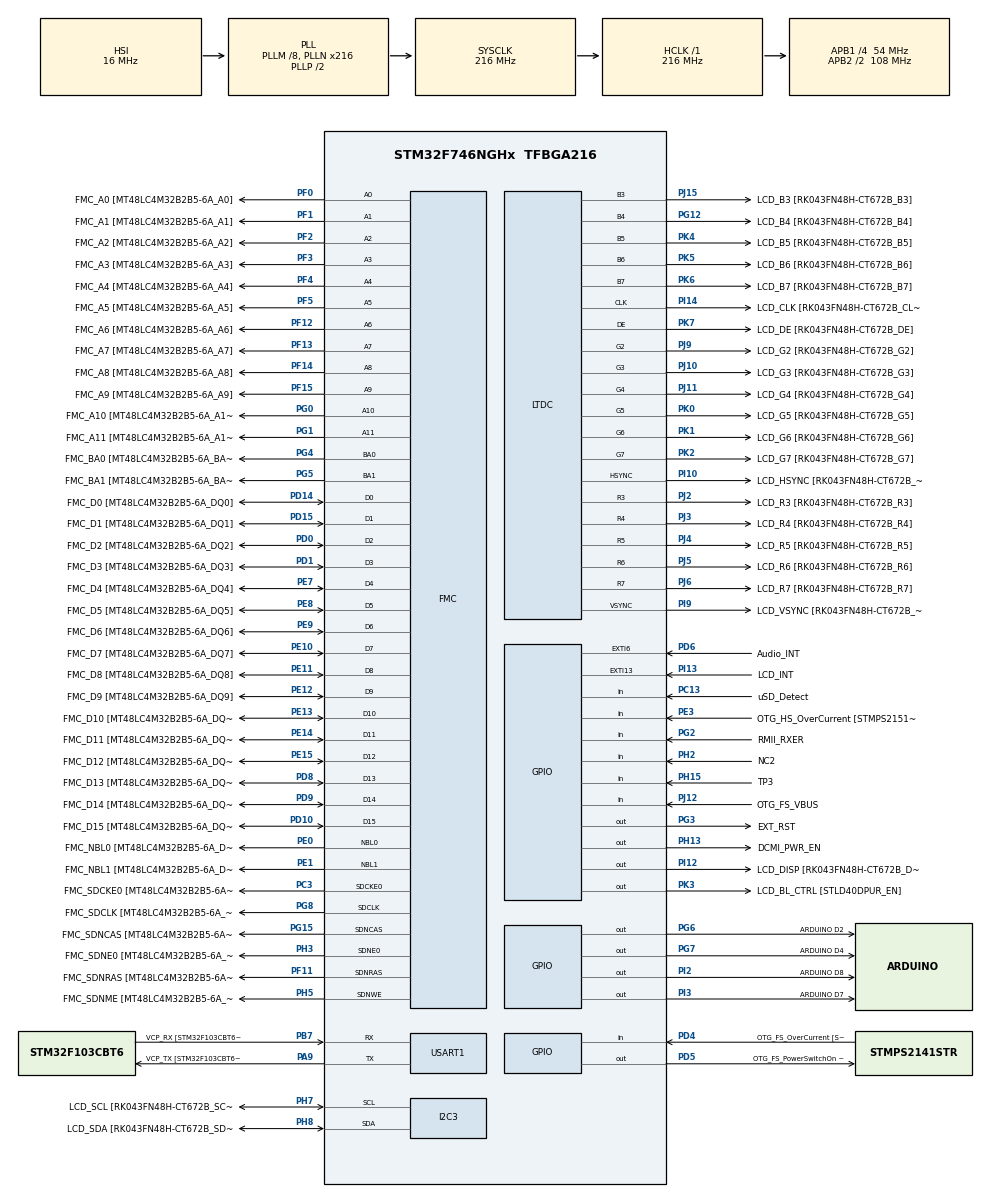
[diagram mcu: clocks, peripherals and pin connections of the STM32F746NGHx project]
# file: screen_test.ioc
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CORTEX_M7.CPU_DCache=Disabled
CORTEX_M7.CPU_ICache=Disabled
CORTEX_M7.PREFETCH_ENABLE=0
FMC.CASLatency1=FMC_SDRAM_CAS_LATENCY_3
FMC.ExitSelfRefreshDelay1=7
FMC.LoadToActiveDelay1=2
FMC.RCDDelay1=2
FMC.RPDelay1=2
FMC.RPDelay2=2
FMC.ReadBurst1=FMC_SDRAM_RBURST_ENABLE
FMC.ReadBurst2=FMC_SDRAM_RBURST_ENABLE
FMC.RowCycleDelay1=7
FMC.RowCycleDelay2=7
FMC.SDClockPeriod1=FMC_SDRAM_CLOCK_PERIOD_2
FMC.SDClockPeriod2=FMC_SDRAM_CLOCK_PERIOD_2
FMC.SelfRefreshTime1=4
FMC.WriteRecoveryTime1=3
FREERTOS.Tasks01=defaultTask,24,128,StartDefaultTask,Default,NULL,Dynamic,NULL,NULL;TSResponse,40,128,StartTSResponse,Default,NULL,Dynamic,NULL,NULL;OscDrawing,40,128,StartOscDrawing,Default,NULL,Dynamic,NULL,NULL
I2C3.Timing=0x20404768
LTDC.ActiveH=SCREEN_HEIGHT
LTDC.ActiveW=SCREEN_WIDTH
LTDC.HBP=13
LTDC.HFP=32
LTDC.HSync=41
LTDC.VSync=10
Mcu.Family=STM32F7
Mcu.Name=STM32F746NGHx
Mcu.Package=TFBGA216
Mcu.UserConstants=SCREEN_WIDTH,480;SCREEN_HEIGHT,272
NVIC.DMA2D_IRQn=true\:5\:0\:false\:false\:true\:true\:true\:true\:true
NVIC.EXTI15_10_IRQn=true\:5\:0\:false\:false\:true\:true\:true\:true\:true
NVIC.PriorityGroup=NVIC_PRIORITYGROUP_4
PA0/WKUP.GPIO_Label=ARDUINO A0
PA0/WKUP.GPIO_Mode=GPIO_MODE_ANALOG
PA0/WKUP.GPIO_PuPd=GPIO_NOPULL
PA0/WKUP.Signal=ADCx_IN0
PA1.GPIO_Label=RMII_REF_CLK [LAN8742A-CZ-TR_REFCLK0]
PA1.Signal=ETH_REF_CLK
PA10.GPIO_Label=OTG_FS_ID
PA10.Signal=USB_OTG_FS_ID
PA11.GPIO_Label=OTG_FS_N
PA11.Signal=USB_OTG_FS_DM
PA12.GPIO_Label=OTG_FS_P
PA12.Signal=USB_OTG_FS_DP
PA13.GPIO_Label=SWDIO
PA13.Signal=SYS_JTMS-SWDIO
PA14.GPIO_Label=SWCLK
PA14.Signal=SYS_JTCK-SWCLK
PA15.GPIO_Label=ARDUINO PWM/D9
PA15.GPIO_ModeDefaultPP=GPIO_MODE_AF_PP
PA15.GPIO_PuPd=GPIO_NOPULL
PA15.GPIO_Speed=GPIO_SPEED_FREQ_LOW
PA15.Signal=S_TIM2_CH1_ETR
PA2.GPIO_Label=RMII_MDIO [LAN8742A-CZ-TR_MDIO]
PA2.Signal=ETH_MDIO
PA3.GPIO_Label=ULPI_D0 [USB3320C-EZK_D0]
PA3.Signal=USB_OTG_HS_ULPI_D0
PA4.GPIO_Label=DCMI_HSYNC
PA4.Signal=DCMI_HSYNC
PA5.GPIO_Label=ULPI_CLK [USB3320C-EZK_CLKOUT]
PA5.Signal=USB_OTG_HS_ULPI_CK
PA6.Signal=DCMI_PIXCLK
PA7.GPIO_Label=RMII_CRS_DV [LAN8742A-CZ-TR_CRS_DV]
PA7.Signal=ETH_CRS_DV
PA8.GPIO_Label=ARDUINO PWM/D10
PA8.GPIO_ModeDefaultPP=GPIO_MODE_AF_PP
PA8.GPIO_PuPd=GPIO_NOPULL
PA8.GPIO_Speed=GPIO_SPEED_FREQ_LOW
PA8.Signal=S_TIM1_CH1
PA9.GPIO_Label=VCP_TX [STM32F103CBT6_PA3]
PA9.GPIO_Mode=GPIO_MODE_AF_PP
PA9.GPIO_PuPd=GPIO_NOPULL
PA9.GPIO_Speed=GPIO_SPEED_FREQ_LOW
PA9.Mode=Asynchronous
PA9.Signal=USART1_TX
PB0.GPIO_Label=ULPI_D1 [USB3320C-EZK_D1]
PB0.Signal=USB_OTG_HS_ULPI_D1
PB1.GPIO_Label=ULPI_D2 [USB3320C-EZK_D2]
PB1.Signal=USB_OTG_HS_ULPI_D2
PB10.GPIO_Label=ULPI_D3 [USB3320C-EZK_D3]
PB10.Signal=USB_OTG_HS_ULPI_D3
PB11.GPIO_Label=ULPI_D4 [USB3320C-EZK_D4]
PB11.Signal=USB_OTG_HS_ULPI_D4
PB12.GPIO_Label=ULPI_D5 [USB3320C-EZK_D5]
PB12.Signal=USB_OTG_HS_ULPI_D5
PB13.GPIO_Label=ULPI_D6 [USB3320C-EZK_D6]
PB13.Signal=USB_OTG_HS_ULPI_D6
PB14.GPIO_Label=ARDUINO MISO/D12
PB14.GPIO_Mode=GPIO_MODE_AF_PP
PB14.GPIO_PuPd=GPIO_NOPULL
PB14.GPIO_Speed=GPIO_SPEED_FREQ_LOW
PB14.Signal=SPI2_MISO
PB15.GPIO_Label=ARDUINO MOSI/PWM/D11
PB15.GPIO_Mode=GPIO_MODE_AF_PP
PB15.GPIO_PuPd=GPIO_NOPULL
PB15.GPIO_Speed=GPIO_SPEED_FREQ_LOW
PB15.Signal=SPI2_MOSI
PB2.Signal=QUADSPI_CLK
PB3.GPIO_Label=SWO
PB3.Signal=SYS_JTDO-SWO
PB4.GPIO_Label=ARDUINO PWM/D3
PB4.GPIO_ModeDefaultPP=GPIO_MODE_AF_PP
PB4.GPIO_PuPd=GPIO_NOPULL
PB4.GPIO_Speed=GPIO_SPEED_FREQ_LOW
PB4.Signal=S_TIM3_CH1
PB5.GPIO_Label=ULPI_D7 [USB3320C-EZK_D7]
PB5.Signal=USB_OTG_HS_ULPI_D7
PB6.GPIO_Label=QSPI_NCS [N25Q128A13EF840E_S]
PB6.Signal=QUADSPI_BK1_NCS
PB7.GPIO_Label=VCP_RX [STM32F103CBT6_PA2]
PB7.GPIO_Mode=GPIO_MODE_AF_PP
PB7.GPIO_PuPd=GPIO_NOPULL
PB7.GPIO_Speed=GPIO_SPEED_FREQ_LOW
PB7.Mode=Asynchronous
PB7.Signal=USART1_RX
PB8.GPIO_Label=ARDUINO SCL/D15
PB8.GPIO_Mode=GPIO_MODE_AF_OD
PB8.GPIO_PuPd=GPIO_NOPULL
PB8.GPIO_Speed=GPIO_SPEED_FREQ_LOW
PB8.Signal=I2C1_SCL
PB9.GPIO_Label=ARDUINO SDA/D14
PB9.GPIO_Mode=GPIO_MODE_AF_OD
PB9.GPIO_PuPd=GPIO_NOPULL
PB9.GPIO_Speed=GPIO_SPEED_FREQ_LOW
PB9.Signal=I2C1_SDA
PC0.GPIO_Label=ULPI_STP [USB3320C-EZK_STP]
PC0.Signal=USB_OTG_HS_ULPI_STP
PC1.GPIO_Label=RMII_MDC [LAN8742A-CZ-TR_MDC]
PC1.Signal=ETH_MDC
PC10.GPIO_Label=SDMMC_D2
PC10.Signal=SDMMC1_D2
PC11.GPIO_Label=SDMMC_D3
PC11.Signal=SDMMC1_D3
PC12.GPIO_Label=SDMMC_CK
PC12.Signal=SDMMC1_CK
PC13.GPIO_Label=uSD_Detect
PC13.Signal=GPIO_Input
PC14/OSC32_IN.GPIO_Label=RCC_OSC32_IN
PC14/OSC32_IN.Signal=RCC_OSC32_IN
PC15/OSC32_OUT.GPIO_Label=RCC_OSC32_OUT
PC15/OSC32_OUT.Signal=RCC_OSC32_OUT
PC2.GPIO_Label=ULPI_DIR [USB3320C-EZK_DIR]
PC2.Signal=USB_OTG_HS_ULPI_DIR
PC3.GPIO_Label=FMC_SDCKE0 [MT48LC4M32B2B5-6A_CKE]
PC3.Mode=SdramChipSelect1_1
PC3.Signal=FMC_SDCKE0
PC4.GPIO_Label=RMII_RXD0 [LAN8742A-CZ-TR_RXD0]
PC4.Signal=ETH_RXD0
PC5.GPIO_Label=RMII_RXD1 [LAN8742A-CZ-TR_RXD1]
PC5.Signal=ETH_RXD1
PC6.GPIO_Label=ARDUINO TX/D1
PC6.Signal=USART6_TX
PC7.GPIO_Label=ARDUINO RX/D0
PC7.Signal=USART6_RX
PC8.Signal=SDMMC1_D0
PC9.Signal=SDMMC1_D1
PD0.GPIO_Label=FMC_D2 [MT48LC4M32B2B5-6A_DQ2]
PD0.Signal=FMC_D2_DA2
PD1.GPIO_Label=FMC_D3 [MT48LC4M32B2B5-6A_DQ3]
PD1.Signal=FMC_D3_DA3
PD10.GPIO_Label=FMC_D15 [MT48LC4M32B2B5-6A_DQ15]
PD10.Signal=FMC_D15_DA15
PD11.GPIO_Label=QSPI_D0 [N25Q128A13EF840E_DQ0]
PD11.Signal=QUADSPI_BK1_IO0
PD12.GPIO_Label=QSPI_D1 [N25Q128A13EF840E_DQ1]
PD12.Signal=QUADSPI_BK1_IO1
PD13.GPIO_Label=QSPI_D3 [N25Q128A13EF840E_DQ3]
PD13.Signal=QUADSPI_BK1_IO3
PD14.GPIO_Label=FMC_D0 [MT48LC4M32B2B5-6A_DQ0]
PD14.Signal=FMC_D0_DA0
PD15.GPIO_Label=FMC_D1 [MT48LC4M32B2B5-6A_DQ1]
PD15.Signal=FMC_D1_DA1
PD2.GPIO_Label=SDMMC_D0
PD2.Signal=SDMMC1_CMD
PD3.GPIO_Label=DCMI_D5
PD3.Signal=DCMI_D5
PD4.GPIO_Label=OTG_FS_OverCurrent [STMPS2141STR_Fault]
PD4.Signal=GPIO_Input
PD5.GPIO_Label=OTG_FS_PowerSwitchOn [STMPS2141STR_EN]
PD5.PinState=GPIO_PIN_SET
PD5.Signal=GPIO_Output
PD6.GPIO_Label=Audio_INT
PD6.GPIO_ModeDefaultEXTI=GPIO_MODE_EVT_RISING
PD6.Signal=GPXTI6
PD7.GPIO_Label=SPDIF_RX0 [74LVC1G04SE_4]
PD7.Signal=SPDIFRX_IN0
PD8.GPIO_Label=FMC_D13 [MT48LC4M32B2B5-6A_DQ13]
PD8.Signal=FMC_D13_DA13
PD9.GPIO_Label=FMC_D14 [MT48LC4M32B2B5-6A_DQ14]
PD9.Signal=FMC_D14_DA14
PE0.GPIO_Label=FMC_NBL0 [MT48LC4M32B2B5-6A_DQM0]
PE0.Signal=FMC_NBL0
PE1.GPIO_Label=FMC_NBL1 [MT48LC4M32B2B5-6A_DQM1]
PE1.Signal=FMC_NBL1
PE10.GPIO_Label=FMC_D7 [MT48LC4M32B2B5-6A_DQ7]
PE10.Signal=FMC_D7_DA7
PE11.GPIO_Label=FMC_D8 [MT48LC4M32B2B5-6A_DQ8]
PE11.Signal=FMC_D8_DA8
PE12.GPIO_Label=FMC_D9 [MT48LC4M32B2B5-6A_DQ9]
PE12.Signal=FMC_D9_DA9
PE13.GPIO_Label=FMC_D10 [MT48LC4M32B2B5-6A_DQ10]
PE13.Signal=FMC_D10_DA10
PE14.GPIO_Label=FMC_D11 [MT48LC4M32B2B5-6A_DQ11]
PE14.Signal=FMC_D11_DA11
PE15.GPIO_Label=FMC_D12 [MT48LC4M32B2B5-6A_DQ12]
PE15.Signal=FMC_D12_DA12
PE2.GPIO_Label=QSPI_D2 [N25Q128A13EF840E_DQ2]
PE2.Signal=QUADSPI_BK1_IO2
PE3.GPIO_Label=OTG_HS_OverCurrent [STMPS2151STR_FAULT]
PE3.Signal=GPIO_Input
PE4.GPIO_Label=LCD_B0 [RK043FN48H-CT672B_B0]
PE4.Signal=LTDC_B0
PE5.GPIO_Label=DCMI_D6
PE5.Signal=DCMI_D6
PE6.GPIO_Label=DCMI_D7
PE6.Signal=DCMI_D7
PE7.GPIO_Label=FMC_D4 [MT48LC4M32B2B5-6A_DQ4]
PE7.Signal=FMC_D4_DA4
PE8.GPIO_Label=FMC_D5 [MT48LC4M32B2B5-6A_DQ5]
PE8.Signal=FMC_D5_DA5
PE9.GPIO_Label=FMC_D6 [MT48LC4M32B2B5-6A_DQ6]
PE9.Signal=FMC_D6_DA6
PF0.GPIO_Label=FMC_A0 [MT48LC4M32B2B5-6A_A0]
PF0.Signal=FMC_A0
PF1.GPIO_Label=FMC_A1 [MT48LC4M32B2B5-6A_A1]
PF1.Signal=FMC_A1
PF10.GPIO_Label=ARDUINO A1
PF10.GPIO_Mode=GPIO_MODE_ANALOG
PF10.GPIO_PuPd=GPIO_NOPULL
PF10.Signal=ADC3_IN8
PF11.GPIO_Label=FMC_SDNRAS [MT48LC4M32B2B5-6A_RAS]
PF11.Signal=FMC_SDNRAS
PF12.GPIO_Label=FMC_A6 [MT48LC4M32B2B5-6A_A6]
PF12.Signal=FMC_A6
PF13.GPIO_Label=FMC_A7 [MT48LC4M32B2B5-6A_A7]
PF13.Signal=FMC_A7
PF14.GPIO_Label=FMC_A8 [MT48LC4M32B2B5-6A_A8]
PF14.Signal=FMC_A8
PF15.GPIO_Label=FMC_A9 [MT48LC4M32B2B5-6A_A9]
PF15.Signal=FMC_A9
PF2.GPIO_Label=FMC_A2 [MT48LC4M32B2B5-6A_A2]
PF2.Signal=FMC_A2
PF3.GPIO_Label=FMC_A3 [MT48LC4M32B2B5-6A_A3]
PF3.Signal=FMC_A3
PF4.GPIO_Label=FMC_A4 [MT48LC4M32B2B5-6A_A4]
PF4.Signal=FMC_A4
PF5.GPIO_Label=FMC_A5 [MT48LC4M32B2B5-6A_A5]
PF5.Signal=FMC_A5
PF6.GPIO_Label=ARDUINO A5
PF6.GPIO_Mode=GPIO_MODE_ANALOG
PF6.GPIO_PuPd=GPIO_NOPULL
PF6.Signal=ADC3_IN4
PF7.GPIO_Label=ARDUINO A4
PF7.GPIO_Mode=GPIO_MODE_ANALOG
PF7.GPIO_PuPd=GPIO_NOPULL
PF7.Signal=ADC3_IN5
PF8.GPIO_Label=ARDUINO A3
PF8.GPIO_Mode=GPIO_MODE_ANALOG
PF8.GPIO_PuPd=GPIO_NOPULL
PF8.Signal=ADC3_IN6
PF9.GPIO_Label=ARDUINO A2
PF9.GPIO_Mode=GPIO_MODE_ANALOG
PF9.GPIO_PuPd=GPIO_NOPULL
PF9.Signal=ADC3_IN7
PG0.GPIO_Label=FMC_A10 [MT48LC4M32B2B5-6A_A10]
PG0.Signal=FMC_A10
PG1.GPIO_Label=FMC_A11 [MT48LC4M32B2B5-6A_A11]
PG1.Signal=FMC_A11
PG10.GPIO_Label=SAI2_SDB [WM8994ECS/R_ADCDAT1]
PG10.Signal=SAI2_SD_B
PG11.GPIO_Label=RMII_TX_EN [LAN8742A-CZ-TR_TXEN]
PG11.Signal=ETH_TX_EN
PG12.GPIO_Label=LCD_B4 [RK043FN48H-CT672B_B4]
PG12.Mode=RGB565
PG12.Signal=LTDC_B4
PG13.GPIO_Label=RMII_TXD0 [LAN8742A-CZ-TR_TXD0]
PG13.Signal=ETH_TXD0
PG14.GPIO_Label=RMII_TXD1 [LAN8742A-CZ-TR_TXD1]
PG14.Signal=ETH_TXD1
PG15.GPIO_Label=FMC_SDNCAS [MT48LC4M32B2B5-6A_CAS]
PG15.Signal=FMC_SDNCAS
PG2.GPIO_Label=RMII_RXER
PG2.Signal=GPIO_Input
PG3.GPIO_Label=EXT_RST
PG3.Signal=GPIO_Output
PG4.GPIO_Label=FMC_BA0 [MT48LC4M32B2B5-6A_BA0]
PG4.Signal=FMC_A14_BA0
PG5.GPIO_Label=FMC_BA1 [MT48LC4M32B2B5-6A_BA1]
PG5.Signal=FMC_A15_BA1
PG6.GPIO_Label=ARDUINO D2
PG6.Signal=GPIO_Output
PG7.GPIO_Label=ARDUINO D4
PG7.Signal=GPIO_Output
PG8.GPIO_Label=FMC_SDCLK [MT48LC4M32B2B5-6A_CLK]
PG8.Signal=FMC_SDCLK
PG9.GPIO_Label=DCMI_VSYNC
PG9.Signal=DCMI_VSYNC
PH0/OSC_IN.GPIO_Label=OSC_25M [NZ2520SB-25.00M_OUT]
PH0/OSC_IN.Mode=HSE-External-Oscillator
PH0/OSC_IN.Signal=RCC_OSC_IN
PH1/OSC_OUT.Mode=HSE-External-Oscillator
PH1/OSC_OUT.Signal=RCC_OSC_OUT
PH10.GPIO_Label=DCMI_D1
PH10.Signal=DCMI_D1
PH11.GPIO_Label=DCMI_D2
PH11.Signal=DCMI_D2
PH12.GPIO_Label=DCMI_D3
PH12.Signal=DCMI_D3
PH13.GPIO_Label=DCMI_PWR_EN
PH13.Signal=GPIO_Output
PH14.GPIO_Label=DCMI_D4
PH14.Signal=DCMI_D4
PH15.GPIO_Label=TP3
PH15.Signal=GPIO_Input
PH2.GPIO_Label=NC2
PH2.Signal=GPIO_Input
PH3.GPIO_Label=FMC_SDNE0 [MT48LC4M32B2B5-6A_CS]
PH3.Mode=SdramChipSelect1_1
PH3.Signal=FMC_SDNE0
PH4.GPIO_Label=ULPI_NXT [USB3320C-EZK_NXT]
PH4.Signal=USB_OTG_HS_ULPI_NXT
PH5.GPIO_Label=FMC_SDNME [MT48LC4M32B2B5-6A_WE]
PH5.Signal=FMC_SDNWE
PH6.GPIO_Label=ARDUINO PWM/D6
PH6.Signal=S_TIM12_CH1
PH7.GPIO_Label=LCD_SCL [RK043FN48H-CT672B_SCL]
PH7.Mode=I2C
PH7.Signal=I2C3_SCL
PH8.GPIO_Label=LCD_SDA [RK043FN48H-CT672B_SDA]
PH8.Mode=I2C
PH8.Signal=I2C3_SDA
PH9.GPIO_Label=DCMI_D0
PH9.Signal=DCMI_D0
PI0.GPIO_Label=ARDUINO PWM/CS/D5
PI0.GPIO_ModeDefaultPP=GPIO_MODE_AF_PP
PI0.GPIO_PuPd=GPIO_NOPULL
PI0.GPIO_Speed=GPIO_SPEED_FREQ_LOW
PI0.Signal=S_TIM5_CH4
PI1.GPIO_Label=ARDUINO SCK/D13
PI1.GPIO_Mode=GPIO_MODE_AF_PP
PI1.GPIO_PuPd=GPIO_NOPULL
PI1.GPIO_Speed=GPIO_SPEED_FREQ_LOW
PI1.Signal=SPI2_SCK
PI10.GPIO_Label=LCD_HSYNC [RK043FN48H-CT672B_HSYNC]
PI10.Mode=RGB565
PI10.Signal=LTDC_HSYNC
PI12.GPIO_Label=LCD_DISP [RK043FN48H-CT672B_DISP] 
PI12.Signal=GPIO_Output
PI13.GPIO_Label=LCD_INT
PI13.GPIO_ModeDefaultEXTI=GPIO_MODE_IT_RISING
PI13.Signal=GPXTI13
PI14.GPIO_Label=LCD_CLK [RK043FN48H-CT672B_CLK]
PI14.Mode=RGB565
PI14.Signal=LTDC_CLK
PI15.GPIO_Label=LCD_R0 [RK043FN48H-CT672B_R0]
PI15.Signal=LTDC_R0
PI2.GPIO_Label=ARDUINO D8
PI2.Signal=GPIO_Output
PI3.GPIO_Label=ARDUINO D7
PI3.Signal=GPIO_Output
PI4.GPIO_Label=SAI2_MCLKA [WM8994ECS/R_MCLK1]
PI4.Signal=SAI2_MCLK_A
PI5.GPIO_Label=SAI2_SCKA [WM8994ECS/R_BCLK1]
PI5.Signal=SAI2_SCK_A
PI6.GPIO_Label=SAI2_SDA [WM8994ECS/R_DACDAT1]
PI6.Signal=SAI2_SD_A
PI7.GPIO_Label=SAI2_FSA [WM8994ECS/R_LRCLK1]
PI7.Signal=SAI2_FS_A
PI8.GPIO_Label=NC1 [TP2]
PI8.Signal=RTC_TS
PI9.GPIO_Label=LCD_VSYNC [RK043FN48H-CT672B_VSYNC]
PI9.Mode=RGB565
PI9.Signal=LTDC_VSYNC
PJ0.GPIO_Label=LCD_R1 [RK043FN48H-CT672B_R1]
PJ0.Signal=LTDC_R1
PJ1.GPIO_Label=LCD_R2 [RK043FN48H-CT672B_R2]
PJ1.Signal=LTDC_R2
PJ10.GPIO_Label=LCD_G3 [RK043FN48H-CT672B_G3]
PJ10.Mode=RGB565
PJ10.Signal=LTDC_G3
PJ11.GPIO_Label=LCD_G4 [RK043FN48H-CT672B_G4]
PJ11.Mode=RGB565
PJ11.Signal=LTDC_G4
PJ12.GPIO_Label=OTG_FS_VBUS
PJ12.Signal=GPIO_Input
PJ13.GPIO_Label=LCD_B1 [RK043FN48H-CT672B_B1]
PJ13.Signal=LTDC_B1
PJ14.GPIO_Label=LCD_B2 [RK043FN48H-CT672B_B2]
PJ14.Signal=LTDC_B2
PJ15.GPIO_Label=LCD_B3 [RK043FN48H-CT672B_B3]
PJ15.Mode=RGB565
PJ15.Signal=LTDC_B3
PJ2.GPIO_Label=LCD_R3 [RK043FN48H-CT672B_R3]
PJ2.Mode=RGB565
PJ2.Signal=LTDC_R3
PJ3.GPIO_Label=LCD_R4 [RK043FN48H-CT672B_R4]
PJ3.Mode=RGB565
PJ3.Signal=LTDC_R4
PJ4.GPIO_Label=LCD_R5 [RK043FN48H-CT672B_R5]
PJ4.Mode=RGB565
PJ4.Signal=LTDC_R5
PJ5.GPIO_Label=LCD_R6 [RK043FN48H-CT672B_R6]
PJ5.Mode=RGB565
PJ5.Signal=LTDC_R6
PJ6.GPIO_Label=LCD_R7 [RK043FN48H-CT672B_R7]
PJ6.Mode=RGB565
PJ6.Signal=LTDC_R7
PJ7.GPIO_Label=LCD_G0 [RK043FN48H-CT672B_G0]
PJ7.Signal=LTDC_G0
PJ8.GPIO_Label=LCD_G1 [RK043FN48H-CT672B_G1]
PJ8.Signal=LTDC_G1
PJ9.GPIO_Label=LCD_G2 [RK043FN48H-CT672B_G2]
PJ9.Mode=RGB565
PJ9.Signal=LTDC_G2
PK0.GPIO_Label=LCD_G5 [RK043FN48H-CT672B_G5]
PK0.Mode=RGB565
PK0.Signal=LTDC_G5
PK1.GPIO_Label=LCD_G6 [RK043FN48H-CT672B_G6]
PK1.Mode=RGB565
PK1.Signal=LTDC_G6
PK2.GPIO_Label=LCD_G7 [RK043FN48H-CT672B_G7]
PK2.Mode=RGB565
PK2.Signal=LTDC_G7
PK3.GPIO_Label=LCD_BL_CTRL [STLD40DPUR_EN]
PK3.Signal=GPIO_Output
PK4.GPIO_Label=LCD_B5 [RK043FN48H-CT672B_B5]
PK4.Mode=RGB565
PK4.Signal=LTDC_B5
PK5.GPIO_Label=LCD_B6 [RK043FN48H-CT672B_B6]
PK5.Mode=RGB565
PK5.Signal=LTDC_B6
PK6.GPIO_Label=LCD_B7 [RK043FN48H-CT672B_B7]
PK6.Mode=RGB565
PK6.Signal=LTDC_B7
PK7.GPIO_Label=LCD_DE [RK043FN48H-CT672B_DE]
PK7.Mode=RGB565
PK7.Signal=LTDC_DE
ProjectManager.HeapSize=0x200
ProjectManager.StackSize=0x400
ProjectManager.TargetToolchain=STM32CubeIDE
RCC.AHBFreq_Value=216000000
RCC.APB1CLKDivider=RCC_HCLK_DIV4
RCC.APB1Freq_Value=54000000
RCC.APB1TimFreq_Value=108000000
RCC.APB2CLKDivider=RCC_HCLK_DIV2
RCC.APB2Freq_Value=108000000
RCC.APB2TimFreq_Value=216000000
RCC.CortexFreq_Value=216000000
RCC.HCLKFreq_Value=216000000
RCC.HSE_VALUE=25000000
RCC.HSI_VALUE=16000000
RCC.LSE_VALUE=32768
RCC.PLLM=8
RCC.PLLN=216
RCC.PLLSAIN=50
RCC.PLLSourceVirtual=RCC_PLLSOURCE_HSI
RCC.SYSCLKFreq_VALUE=216000000
RCC.SYSCLKSource=RCC_SYSCLKSOURCE_PLLCLK
RCC.USBFreq_Value=216000000
RCC.VCOOutputFreq_Value=432000000
SH.ADCx_IN0.0=ADC3_IN0
SH.FMC_A0.0=FMC_A0,12b-sda1
SH.FMC_A1.0=FMC_A1,12b-sda1
SH.FMC_A10.0=FMC_A10,12b-sda1
SH.FMC_A11.0=FMC_A11,12b-sda1
SH.FMC_A14_BA0.0=FMC_BA0,FourSdramBanks1
SH.FMC_A15_BA1.0=FMC_BA1,FourSdramBanks1
SH.FMC_A2.0=FMC_A2,12b-sda1
SH.FMC_A3.0=FMC_A3,12b-sda1
SH.FMC_A4.0=FMC_A4,12b-sda1
SH.FMC_A5.0=FMC_A5,12b-sda1
SH.FMC_A6.0=FMC_A6,12b-sda1
SH.FMC_A7.0=FMC_A7,12b-sda1
SH.FMC_A8.0=FMC_A8,12b-sda1
SH.FMC_A9.0=FMC_A9,12b-sda1
SH.FMC_D0_DA0.0=FMC_D0,sd-16b-d1
SH.FMC_D10_DA10.0=FMC_D10,sd-16b-d1
SH.FMC_D11_DA11.0=FMC_D11,sd-16b-d1
SH.FMC_D12_DA12.0=FMC_D12,sd-16b-d1
SH.FMC_D13_DA13.0=FMC_D13,sd-16b-d1
SH.FMC_D14_DA14.0=FMC_D14,sd-16b-d1
SH.FMC_D15_DA15.0=FMC_D15,sd-16b-d1
SH.FMC_D1_DA1.0=FMC_D1,sd-16b-d1
SH.FMC_D2_DA2.0=FMC_D2,sd-16b-d1
SH.FMC_D3_DA3.0=FMC_D3,sd-16b-d1
SH.FMC_D4_DA4.0=FMC_D4,sd-16b-d1
SH.FMC_D5_DA5.0=FMC_D5,sd-16b-d1
SH.FMC_D6_DA6.0=FMC_D6,sd-16b-d1
SH.FMC_D7_DA7.0=FMC_D7,sd-16b-d1
SH.FMC_D8_DA8.0=FMC_D8,sd-16b-d1
SH.FMC_D9_DA9.0=FMC_D9,sd-16b-d1
SH.FMC_NBL0.0=FMC_NBL0,Sd2ByteEnable1
SH.FMC_NBL1.0=FMC_NBL1,Sd2ByteEnable1
SH.FMC_SDCLK.0=FMC_SDCLK,12b-sda1
SH.FMC_SDNCAS.0=FMC_SDNCAS,12b-sda1
SH.FMC_SDNRAS.0=FMC_SDNRAS,12b-sda1
SH.FMC_SDNWE.0=FMC_SDNWE,12b-sda1
SH.S_TIM12_CH1.0=TIM12_CH1
SH.S_TIM1_CH1.0=TIM1_CH1
SH.S_TIM2_CH1_ETR.0=TIM2_CH1
SH.S_TIM3_CH1.0=TIM3_CH1
SH.S_TIM5_CH4.0=TIM5_CH4
USART1.VirtualMode-Asynchronous=VM_ASYNC
VP_DMA2D_VS_DMA2D.Mode=DMA2D_Activate
VP_FREERTOS_VS_CMSIS_V2.Mode=CMSIS_V2
board=STM32F746G-DISCO

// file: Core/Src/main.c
/* USER CODE BEGIN Header */
/**
  ******************************************************************************
  * @file           : main.c
  * @brief          : Main program body
  ******************************************************************************
  * @attention
  *
  * Copyright (c) 2025 STMicroelectronics.
  * All rights reserved.
  *
  * This software is licensed under terms that can be found in the LICENSE file
  * in the root directory of this software component.
  * If no LICENSE file comes with this software, it is provided AS-IS.
  *
  ******************************************************************************
  */
/* USER CODE END Header */
#include "main.h"
#include "cmsis_os.h"

/* USER CODE BEGIN Includes */
#include "stlogo.h"
#include <stdio.h>
#include "fir_design.h"
#include "math.h"
#include "string.h"
#include "draw_utils.h"
/* USER CODE END Includes */

/* USER CODE BEGIN PTD */

/* in draw_utils.h
typedef enum
{
    OSC,
    SIG,
    FIL,
	PUR,
} mode_t;

typedef enum
{
	SIN,
	SQR,
	TRI,
} waveform_t;
*/

/* USER CODE END PTD */

/* USER CODE BEGIN PD */

/* in draw_utils.h
#define SCREEN_X 480
#define SCREEN_Y 272
#define FILTER_SELECT_BOX_X 95
#define FILTER_SELECT_BOX_Y 15
#define WAVEFORM_SELECT_BOX_X 160
#define WAVEFORM_SELECT_BOX_Y 50
#define FULL_SCREEN_BUT_X 160
#define FULL_SCREEN_BUT_Y 40
*/

/* USER CODE END PD */

DMA2D_HandleTypeDef hdma2d;

I2C_HandleTypeDef hi2c3;

LTDC_HandleTypeDef hltdc;

UART_HandleTypeDef huart1;

SDRAM_HandleTypeDef hsdram1;

/* Definitions for defaultTask */
osThreadId_t defaultTaskHandle;
const osThreadAttr_t defaultTask_attributes = {
  .name = "defaultTask",
  .stack_size = 128 * 4,
  .priority = (osPriority_t) osPriorityNormal,
};
/* Definitions for TSResponse */
osThreadId_t TSResponseHandle;
const osThreadAttr_t TSResponse_attributes = {
  .name = "TSResponse",
  .stack_size = 128 * 4,
  .priority = (osPriority_t) osPriorityHigh,
};
/* Definitions for OscDrawing */
osThreadId_t OscDrawingHandle;
const osThreadAttr_t OscDrawing_attributes = {
  .name = "OscDrawing",
  .stack_size = 128 * 4,
  .priority = (osPriority_t) osPriorityHigh,
};
/* USER CODE BEGIN PV */

/*in draw_utils.c
mode_t current_mode = OSC;
fir_type_t current_filter;
waveform_t current_waveform;
float waveform_mag = 1;
float waveform_freq = 10000000;
float waveform_duty = 0.3;
float osc_Vpp, osc_T, osc_V, osc_trigger, osc_freq;
int anomaly_flag = 0;
int test_flag = 0;
uint8_t databuffer[400];
uint8_t drawbuffer[400];
uint8_t prevdrawbuffer[400];
uint16_t trigger_index = 199;
uint8_t apply_filter = 0;
*/

/* USER CODE END PV */

void SystemClock_Config(void);
static void MX_GPIO_Init(void);
static void MX_USART1_UART_Init(void);
static void MX_FMC_Init(void);
static void MX_LTDC_Init(void);
static void MX_DMA2D_Init(void);
static void MX_I2C3_Init(void);
void StartDefaultTask(void *argument);
void StartTSResponse(void *argument);
void StartOscDrawing(void *argument);

/* USER CODE BEGIN PFP */

/* in draw_utils.h
void Display_DemoDescription(void);
void Display_Osc(void);
void Display_Sig_gen(void);
void Display_Filter(void);
void Display_pure(void);
void Select_Filter(uint16_t);
void Select_Waveform(uint16_t);
void touch_screen_response(void);
void draw_waveform(void);
void buffer_maker(float val, const char *prefix, char *out_buffer);
void float_to_string(float val, char *str, int decimal_places);
*/

/* USER CODE END PFP */

/* USER CODE BEGIN 0 */
/* in draw_utils.c
uint8_t status = 0, gesture = 0;
uint8_t  lcd_status = LCD_OK, touch_screen_it = 0;
TS_StateTypeDef touch_screen_state;
*/
/* USER CODE END 0 */

int main(void)
{

  /* MCU Configuration--------------------------------------------------------*/

  /* Reset of all peripherals, Initializes the Flash interface and the Systick. */
  HAL_Init();

  /* Configure the system clock */
  SystemClock_Config();

  /* Initialize all configured peripherals */
  MX_GPIO_Init();
  MX_USART1_UART_Init();
  MX_FMC_Init();
  MX_LTDC_Init();
  MX_DMA2D_Init();
  MX_I2C3_Init();
  /* USER CODE BEGIN 2 */
  BSP_LED_Init(LED1);

  /* Initialize the LCD */
  lcd_status = BSP_LCD_Init();
  if (lcd_status != LCD_OK)
  {
    Error_Handler();
  }
  BSP_LCD_LayerDefaultInit(LTDC_ACTIVE_LAYER, LCD_FRAME_BUFFER);

  /* Get the LCD X and Y sizes */
  uint32_t lcd_x_size = BSP_LCD_GetXSize();
  uint32_t lcd_y_size = BSP_LCD_GetYSize();

  Display_DemoDescription();

  /* Set the LCD background and text colors */
  BSP_LCD_DisplayOn();
  BSP_LCD_Clear(LCD_COLOR_WHITE);
  BSP_LCD_SetBackColor(LCD_COLOR_WHITE);
  BSP_LCD_SetTextColor(LCD_COLOR_BLUE);

  BSP_LCD_DrawRect(50, 50, 100, 50);

  /* Display a string at the center of the screen */
  BSP_LCD_DisplayStringAt(0, LINE(5), (uint8_t *)"LCD Test", CENTER_MODE);

  /* Draw a rectangle */
  BSP_LCD_SetTextColor(LCD_COLOR_RED);

  /* Draw a filled circle */
  BSP_LCD_SetTextColor(LCD_COLOR_GREEN);
  BSP_LCD_FillCircle(150, 150, 30);

  /* Display the sizes on the LCD */
  char size_message[50];
  snprintf(size_message, sizeof(size_message), "X: %lu, Y: %lu", lcd_x_size, lcd_y_size);
  BSP_LCD_DisplayStringAt(0, LINE(6), (uint8_t *)size_message, CENTER_MODE);

  status = BSP_TS_Init(SCREEN_WIDTH, SCREEN_HEIGHT);
  BSP_TS_ITConfig();
  status = BSP_TS_ITGetStatus();

  /* ping test start */
  BSP_LCD_Clear(LCD_COLOR_BLACK);
  BSP_LCD_SetBackColor(LCD_COLOR_BLACK);
  BSP_LCD_SetTextColor(LCD_COLOR_YELLOW);

  Display_Osc();
  for(int i = 0; i < 400; ++i){
	  databuffer[i] = i % 255;
  }

  /* USER CODE END 2 */

  /* Init scheduler */
  osKernelInitialize();

  /* Create the thread(s) */
  /* creation of defaultTask */
  defaultTaskHandle = osThreadNew(StartDefaultTask, NULL, &defaultTask_attributes);

  /* creation of TSResponse */
  TSResponseHandle = osThreadNew(StartTSResponse, NULL, &TSResponse_attributes);

  /* creation of OscDrawing */
  OscDrawingHandle = osThreadNew(StartOscDrawing, NULL, &OscDrawing_attributes);

  /* Start scheduler */
  osKernelStart();

  /* We should never get here as control is now taken by the scheduler */

  /* Infinite loop */
  /* USER CODE BEGIN WHILE */
  while (1)
  {
	  if(touch_screen_it)
	  {
//		  touch_screen_response();
//		BSP_TS_ITClear();
//		BSP_TS_GetState(&touch_screen_state);
//		BSP_TS_Get_GestureId(&touch_screen_state);
//		if(touch_screen_state.gestureId != 0)
//			gesture = touch_screen_state.gestureId;
//		touch_screen_it = 0;
//		//	BSP_LCD_DisplayStringAt(0, LINE(5), (uint8_t *)"Touched", CENTER_MODE);
//		if(current_mode == PUR){
//			if(touch_screen_state.touchY[0] < SCREEN_Y - FULL_SCREEN_BUT_Y){
//				Display_Osc();
//				current_mode = OSC;
//				continue;
//			}
//		}
//		if(touch_screen_state.touchX[0] < 320 && touch_screen_state.touchX[0] > 160 && touch_screen_state.touchY[0] < 50){
//			Display_Sig_gen();
//			current_mode = SIG;
//		}
//		if(touch_screen_state.touchX[0] < 160 && touch_screen_state.touchY[0] < 50){
//			current_mode = OSC;
//			Display_Osc();
//		}
//		if(touch_screen_state.touchX[0] > 320 && touch_screen_state.touchY[0] < 50){
//			Display_Filter();
//			current_mode = FIL;
//		}
//		switch(current_mode){
//		case OSC:
//			if(touch_screen_state.touchY[0] > SCREEN_Y - FULL_SCREEN_BUT_Y && touch_screen_state.touchX[0] > SCREEN_X - FULL_SCREEN_BUT_X){
//				current_mode = PUR;
//				Display_pure();
//			}
//			break;
//		case SIG:
//			if(touch_screen_state.touchY[0] > 100 && touch_screen_state.touchY[0] < 200){
//				for(uint16_t j = 0; j < 3; j++){
//					if((touch_screen_state.touchX[0] > (WAVEFORM_SELECT_BOX_X*j)) && (touch_screen_state.touchX[0] < WAVEFORM_SELECT_BOX_X * (1 + j))){
//						Select_Waveform(j);
//						break;
//					}
//				}
//			}
//			break;
//		case FIL:
//			if(touch_screen_state.touchY[0] > 222){
//				for(uint16_t j = 0; j < 4; ++j){
//					if((touch_screen_state.touchX[0] > FILTER_SELECT_BOX_X * (j + 1)) && (touch_screen_state.touchX[0] < FILTER_SELECT_BOX_X * (j + 2))){
//						Select_Filter(j);
//						break;
//					}
//				}
//			}
//			break;
//		default:
//			break;
//		}
	  }
    /* USER CODE END WHILE */

  }
}

void SystemClock_Config(void)
{
  RCC_OscInitTypeDef RCC_OscInitStruct = {0};
  RCC_ClkInitTypeDef RCC_ClkInitStruct = {0};

  /** Configure the main internal regulator output voltage
  */
  __HAL_RCC_PWR_CLK_ENABLE();
  __HAL_PWR_VOLTAGESCALING_CONFIG(PWR_REGULATOR_VOLTAGE_SCALE1);

  /** Initializes the RCC Oscillators according to the specified parameters
  * in the RCC_OscInitTypeDef structure.
  */
  RCC_OscInitStruct.OscillatorType = RCC_OSCILLATORTYPE_HSI;
  RCC_OscInitStruct.HSIState = RCC_HSI_ON;
  RCC_OscInitStruct.HSICalibrationValue = RCC_HSICALIBRATION_DEFAULT;
  RCC_OscInitStruct.PLL.PLLState = RCC_PLL_ON;
  RCC_OscInitStruct.PLL.PLLSource = RCC_PLLSOURCE_HSI;
  RCC_OscInitStruct.PLL.PLLM = 8;
  RCC_OscInitStruct.PLL.PLLN = 216;
  RCC_OscInitStruct.PLL.PLLP = RCC_PLLP_DIV2;
  RCC_OscInitStruct.PLL.PLLQ = 2;
  if (HAL_RCC_OscConfig(&RCC_OscInitStruct) != HAL_OK)
  {
    Error_Handler();
  }

  /** Activate the Over-Drive mode
  */
  if (HAL_PWREx_EnableOverDrive() != HAL_OK)
  {
    Error_Handler();
  }

  /** Initializes the CPU, AHB and APB buses clocks
  */
  RCC_ClkInitStruct.ClockType = RCC_CLOCKTYPE_HCLK|RCC_CLOCKTYPE_SYSCLK
                              |RCC_CLOCKTYPE_PCLK1|RCC_CLOCKTYPE_PCLK2;
  RCC_ClkInitStruct.SYSCLKSource = RCC_SYSCLKSOURCE_PLLCLK;
  RCC_ClkInitStruct.AHBCLKDivider = RCC_SYSCLK_DIV1;
  RCC_ClkInitStruct.APB1CLKDivider = RCC_HCLK_DIV4;
  RCC_ClkInitStruct.APB2CLKDivider = RCC_HCLK_DIV2;

  if (HAL_RCC_ClockConfig(&RCC_ClkInitStruct, FLASH_LATENCY_7) != HAL_OK)
  {
    Error_Handler();
  }
}

static void MX_DMA2D_Init(void)
{

  hdma2d.Instance = DMA2D;
  hdma2d.Init.Mode = DMA2D_M2M;
  hdma2d.Init.ColorMode = DMA2D_OUTPUT_ARGB8888;
  hdma2d.Init.OutputOffset = 0;
  hdma2d.LayerCfg[1].InputOffset = 0;
  hdma2d.LayerCfg[1].InputColorMode = DMA2D_INPUT_ARGB8888;
  hdma2d.LayerCfg[1].AlphaMode = DMA2D_NO_MODIF_ALPHA;
  hdma2d.LayerCfg[1].InputAlpha = 0;
  if (HAL_DMA2D_Init(&hdma2d) != HAL_OK)
  {
    Error_Handler();
  }
  if (HAL_DMA2D_ConfigLayer(&hdma2d, 1) != HAL_OK)
  {
    Error_Handler();
  }

}

static void MX_I2C3_Init(void)
{

  hi2c3.Instance = I2C3;
  hi2c3.Init.Timing = 0x20404768;
  hi2c3.Init.OwnAddress1 = 0;
  hi2c3.Init.AddressingMode = I2C_ADDRESSINGMODE_7BIT;
  hi2c3.Init.DualAddressMode = I2C_DUALADDRESS_DISABLE;
  hi2c3.Init.OwnAddress2 = 0;
  hi2c3.Init.OwnAddress2Masks = I2C_OA2_NOMASK;
  hi2c3.Init.GeneralCallMode = I2C_GENERALCALL_DISABLE;
  hi2c3.Init.NoStretchMode = I2C_NOSTRETCH_DISABLE;
  if (HAL_I2C_Init(&hi2c3) != HAL_OK)
  {
    Error_Handler();
  }

  /** Configure Analogue filter
  */
  if (HAL_I2CEx_ConfigAnalogFilter(&hi2c3, I2C_ANALOGFILTER_ENABLE) != HAL_OK)
  {
    Error_Handler();
  }

  /** Configure Digital filter
  */
  if (HAL_I2CEx_ConfigDigitalFilter(&hi2c3, 0) != HAL_OK)
  {
    Error_Handler();
  }

}

static void MX_LTDC_Init(void)
{

  LTDC_LayerCfgTypeDef pLayerCfg = {0};
  LTDC_LayerCfgTypeDef pLayerCfg1 = {0};

  hltdc.Instance = LTDC;
  hltdc.Init.HSPolarity = LTDC_HSPOLARITY_AL;
  hltdc.Init.VSPolarity = LTDC_VSPOLARITY_AL;
  hltdc.Init.DEPolarity = LTDC_DEPOLARITY_AL;
  hltdc.Init.PCPolarity = LTDC_PCPOLARITY_IPC;
  hltdc.Init.HorizontalSync = 40;
  hltdc.Init.VerticalSync = 9;
  hltdc.Init.AccumulatedHBP = 53;
  hltdc.Init.AccumulatedVBP = 11;
  hltdc.Init.AccumulatedActiveW = 533;
  hltdc.Init.AccumulatedActiveH = 283;
  hltdc.Init.TotalWidth = 565;
  hltdc.Init.TotalHeigh = 285;
  hltdc.Init.Backcolor.Blue = 0;
  hltdc.Init.Backcolor.Green = 0;
  hltdc.Init.Backcolor.Red = 0;
  if (HAL_LTDC_Init(&hltdc) != HAL_OK)
  {
    Error_Handler();
  }
  pLayerCfg.WindowX0 = 0;
  pLayerCfg.WindowX1 = 0;
  pLayerCfg.WindowY0 = 0;
  pLayerCfg.WindowY1 = 0;
  pLayerCfg.PixelFormat = LTDC_PIXEL_FORMAT_ARGB8888;
  pLayerCfg.Alpha = 0;
  pLayerCfg.Alpha0 = 0;
  pLayerCfg.BlendingFactor1 = LTDC_BLENDING_FACTOR1_CA;
  pLayerCfg.BlendingFactor2 = LTDC_BLENDING_FACTOR2_CA;
  pLayerCfg.FBStartAdress = 0;
  pLayerCfg.ImageWidth = 0;
  pLayerCfg.ImageHeight = 0;
  pLayerCfg.Backcolor.Blue = 0;
  pLayerCfg.Backcolor.Green = 0;
  pLayerCfg.Backcolor.Red = 0;
  if (HAL_LTDC_ConfigLayer(&hltdc, &pLayerCfg, 0) != HAL_OK)
  {
    Error_Handler();
  }
  pLayerCfg1.WindowX0 = 0;
  pLayerCfg1.WindowX1 = 0;
  pLayerCfg1.WindowY0 = 0;
  pLayerCfg1.WindowY1 = 0;
  pLayerCfg1.PixelFormat = LTDC_PIXEL_FORMAT_ARGB8888;
  pLayerCfg1.Alpha = 0;
  pLayerCfg1.Alpha0 = 0;
  pLayerCfg1.BlendingFactor1 = LTDC_BLENDING_FACTOR1_CA;
  pLayerCfg1.BlendingFactor2 = LTDC_BLENDING_FACTOR2_CA;
  pLayerCfg1.FBStartAdress = 0;
  pLayerCfg1.ImageWidth = 0;
  pLayerCfg1.ImageHeight = 0;
  pLayerCfg1.Backcolor.Blue = 0;
  pLayerCfg1.Backcolor.Green = 0;
  pLayerCfg1.Backcolor.Red = 0;
  if (HAL_LTDC_ConfigLayer(&hltdc, &pLayerCfg1, 1) != HAL_OK)
  {
    Error_Handler();
  }

}

static void MX_USART1_UART_Init(void)
{

  huart1.Instance = USART1;
  huart1.Init.BaudRate = 115200;
  huart1.Init.WordLength = UART_WORDLENGTH_8B;
  huart1.Init.StopBits = UART_STOPBITS_1;
  huart1.Init.Parity = UART_PARITY_NONE;
  huart1.Init.Mode = UART_MODE_TX_RX;
  huart1.Init.HwFlowCtl = UART_HWCONTROL_NONE;
  huart1.Init.OverSampling = UART_OVERSAMPLING_16;
  huart1.Init.OneBitSampling = UART_ONE_BIT_SAMPLE_DISABLE;
  huart1.AdvancedInit.AdvFeatureInit = UART_ADVFEATURE_NO_INIT;
  if (HAL_UART_Init(&huart1) != HAL_OK)
  {
    Error_Handler();
  }

}

/* FMC initialization function */
static void MX_FMC_Init(void)
{

  FMC_SDRAM_TimingTypeDef SdramTiming = {0};

  /** Perform the SDRAM1 memory initialization sequence
  */
  hsdram1.Instance = FMC_SDRAM_DEVICE;
  /* hsdram1.Init */
  hsdram1.Init.SDBank = FMC_SDRAM_BANK1;
  hsdram1.Init.ColumnBitsNumber = FMC_SDRAM_COLUMN_BITS_NUM_8;
  hsdram1.Init.RowBitsNumber = FMC_SDRAM_ROW_BITS_NUM_12;
  hsdram1.Init.MemoryDataWidth = FMC_SDRAM_MEM_BUS_WIDTH_16;
  hsdram1.Init.InternalBankNumber = FMC_SDRAM_INTERN_BANKS_NUM_4;
  hsdram1.Init.CASLatency = FMC_SDRAM_CAS_LATENCY_3;
  hsdram1.Init.WriteProtection = FMC_SDRAM_WRITE_PROTECTION_DISABLE;
  hsdram1.Init.SDClockPeriod = FMC_SDRAM_CLOCK_PERIOD_2;
  hsdram1.Init.ReadBurst = FMC_SDRAM_RBURST_ENABLE;
  hsdram1.Init.ReadPipeDelay = FMC_SDRAM_RPIPE_DELAY_0;
  /* SdramTiming */
  SdramTiming.LoadToActiveDelay = 2;
  SdramTiming.ExitSelfRefreshDelay = 7;
  SdramTiming.SelfRefreshTime = 4;
  SdramTiming.RowCycleDelay = 7;
  SdramTiming.WriteRecoveryTime = 3;
  SdramTiming.RPDelay = 2;
  SdramTiming.RCDDelay = 2;

  if (HAL_SDRAM_Init(&hsdram1, &SdramTiming) != HAL_OK)
  {
    Error_Handler( );
  }

}

static void MX_GPIO_Init(void)
{
  GPIO_InitTypeDef GPIO_InitStruct = {0};

  /* GPIO Ports Clock Enable */
  __HAL_RCC_GPIOE_CLK_ENABLE();
  __HAL_RCC_GPIOG_CLK_ENABLE();
  __HAL_RCC_GPIOB_CLK_ENABLE();
  __HAL_RCC_GPIOD_CLK_ENABLE();
  __HAL_RCC_GPIOC_CLK_ENABLE();
  __HAL_RCC_GPIOA_CLK_ENABLE();
  __HAL_RCC_GPIOJ_CLK_ENABLE();
  __HAL_RCC_GPIOI_CLK_ENABLE();
  __HAL_RCC_GPIOK_CLK_ENABLE();
  __HAL_RCC_GPIOF_CLK_ENABLE();
  __HAL_RCC_GPIOH_CLK_ENABLE();

  /*Configure GPIO pin Output Level */
  HAL_GPIO_WritePin(OTG_FS_PowerSwitchOn_GPIO_Port, OTG_FS_PowerSwitchOn_Pin, GPIO_PIN_SET);

  /*Configure GPIO pin Output Level */
  HAL_GPIO_WritePin(GPIOI, ARDUINO_D7_Pin|ARDUINO_D8_Pin|LCD_DISP_Pin, GPIO_PIN_RESET);

  /*Configure GPIO pin Output Level */
  HAL_GPIO_WritePin(LCD_BL_CTRL_GPIO_Port, LCD_BL_CTRL_Pin, GPIO_PIN_RESET);

  /*Configure GPIO pin Output Level */
  HAL_GPIO_WritePin(DCMI_PWR_EN_GPIO_Port, DCMI_PWR_EN_Pin, GPIO_PIN_RESET);

  /*Configure GPIO pin Output Level */
  HAL_GPIO_WritePin(GPIOG, ARDUINO_D4_Pin|ARDUINO_D2_Pin|EXT_RST_Pin, GPIO_PIN_RESET);

  /*Configure GPIO pin : OTG_HS_OverCurrent_Pin */
  GPIO_InitStruct.Pin = OTG_HS_OverCurrent_Pin;
  GPIO_InitStruct.Mode = GPIO_MODE_INPUT;
  GPIO_InitStruct.Pull = GPIO_NOPULL;
  HAL_GPIO_Init(OTG_HS_OverCurrent_GPIO_Port, &GPIO_InitStruct);

  /*Configure GPIO pin : QSPI_D2_Pin */
  GPIO_InitStruct.Pin = QSPI_D2_Pin;
  GPIO_InitStruct.Mode = GPIO_MODE_AF_PP;
  GPIO_InitStruct.Pull = GPIO_NOPULL;
  GPIO_InitStruct.Speed = GPIO_SPEED_FREQ_VERY_HIGH;
  GPIO_InitStruct.Alternate = GPIO_AF9_QUADSPI;
  HAL_GPIO_Init(QSPI_D2_GPIO_Port, &GPIO_InitStruct);

  /*Configure GPIO pins : RMII_TXD1_Pin RMII_TXD0_Pin RMII_TX_EN_Pin */
  GPIO_InitStruct.Pin = RMII_TXD1_Pin|RMII_TXD0_Pin|RMII_TX_EN_Pin;
  GPIO_InitStruct.Mode = GPIO_MODE_AF_PP;
  GPIO_InitStruct.Pull = GPIO_NOPULL;
  GPIO_InitStruct.Speed = GPIO_SPEED_FREQ_VERY_HIGH;
  GPIO_InitStruct.Alternate = GPIO_AF11_ETH;
  HAL_GPIO_Init(GPIOG, &GPIO_InitStruct);

  /*Configure GPIO pins : ARDUINO_SCL_D15_Pin ARDUINO_SDA_D14_Pin */
  GPIO_InitStruct.Pin = ARDUINO_SCL_D15_Pin|ARDUINO_SDA_D14_Pin;
  GPIO_InitStruct.Mode = GPIO_MODE_AF_OD;
  GPIO_InitStruct.Pull = GPIO_NOPULL;
  GPIO_InitStruct.Speed = GPIO_SPEED_FREQ_LOW;
  GPIO_InitStruct.Alternate = GPIO_AF4_I2C1;
  HAL_GPIO_Init(GPIOB, &GPIO_InitStruct);

  /*Configure GPIO pins : ULPI_D7_Pin ULPI_D6_Pin ULPI_D5_Pin ULPI_D3_Pin
                           ULPI_D2_Pin ULPI_D1_Pin ULPI_D4_Pin */
  GPIO_InitStruct.Pin = ULPI_D7_Pin|ULPI_D6_Pin|ULPI_D5_Pin|ULPI_D3_Pin
                          |ULPI_D2_Pin|ULPI_D1_Pin|ULPI_D4_Pin;
  GPIO_InitStruct.Mode = GPIO_MODE_AF_PP;
  GPIO_InitStruct.Pull = GPIO_NOPULL;
  GPIO_InitStruct.Speed = GPIO_SPEED_FREQ_VERY_HIGH;
  GPIO_InitStruct.Alternate = GPIO_AF10_OTG_HS;
  HAL_GPIO_Init(GPIOB, &GPIO_InitStruct);

  /*Configure GPIO pin : ARDUINO_PWM_D3_Pin */
  GPIO_InitStruct.Pin = ARDUINO_PWM_D3_Pin;
  GPIO_InitStruct.Mode = GPIO_MODE_AF_PP;
  GPIO_InitStruct.Pull = GPIO_NOPULL;
  GPIO_InitStruct.Speed = GPIO_SPEED_FREQ_LOW;
  GPIO_InitStruct.Alternate = GPIO_AF2_TIM3;
  HAL_GPIO_Init(ARDUINO_PWM_D3_GPIO_Port, &GPIO_InitStruct);

  /*Configure GPIO pin : SPDIF_RX0_Pin */
  GPIO_InitStruct.Pin = SPDIF_RX0_Pin;
  GPIO_InitStruct.Mode = GPIO_MODE_AF_PP;
  GPIO_InitStruct.Pull = GPIO_NOPULL;
  GPIO_InitStruct.Speed = GPIO_SPEED_FREQ_LOW;
  GPIO_InitStruct.Alternate = GPIO_AF8_SPDIFRX;
  HAL_GPIO_Init(SPDIF_RX0_GPIO_Port, &GPIO_InitStruct);

  /*Configure GPIO pins : SDMMC_CK_Pin SDMMC_D3_Pin SDMMC_D2_Pin PC9
                           PC8 */
  GPIO_InitStruct.Pin = SDMMC_CK_Pin|SDMMC_D3_Pin|SDMMC_D2_Pin|GPIO_PIN_9
                          |GPIO_PIN_8;
  GPIO_InitStruct.Mode = GPIO_MODE_AF_PP;
  GPIO_InitStruct.Pull = GPIO_NOPULL;
  GPIO_InitStruct.Speed = GPIO_SPEED_FREQ_VERY_HIGH;
  GPIO_InitStruct.Alternate = GPIO_AF12_SDMMC1;
  HAL_GPIO_Init(GPIOC, &GPIO_InitStruct);

  /*Configure GPIO pin : ARDUINO_PWM_D9_Pin */
  GPIO_InitStruct.Pin = ARDUINO_PWM_D9_Pin;
  GPIO_InitStruct.Mode = GPIO_MODE_AF_PP;
  GPIO_InitStruct.Pull = GPIO_NOPULL;
  GPIO_InitStruct.Speed = GPIO_SPEED_FREQ_LOW;
  GPIO_InitStruct.Alternate = GPIO_AF1_TIM2;
  HAL_GPIO_Init(ARDUINO_PWM_D9_GPIO_Port, &GPIO_InitStruct);

  /*Configure GPIO pins : DCMI_D6_Pin DCMI_D7_Pin */
  GPIO_InitStruct.Pin = DCMI_D6_Pin|DCMI_D7_Pin;
  GPIO_InitStruct.Mode = GPIO_MODE_AF_PP;
  GPIO_InitStruct.Pull = GPIO_NOPULL;
  GPIO_InitStruct.Speed = GPIO_SPEED_FREQ_LOW;
  GPIO_InitStruct.Alternate = GPIO_AF13_DCMI;
  HAL_GPIO_Init(GPIOE, &GPIO_InitStruct);

  /*Configure GPIO pin : QSPI_NCS_Pin */
  GPIO_InitStruct.Pin = QSPI_NCS_Pin;
  GPIO_InitStruct.Mode = GPIO_MODE_AF_PP;
  GPIO_InitStruct.Pull = GPIO_NOPULL;
  GPIO_InitStruct.Speed = GPIO_SPEED_FREQ_VERY_HIGH;
  GPIO_InitStruct.Alternate = GPIO_AF10_QUADSPI;
  HAL_GPIO_Init(QSPI_NCS_GPIO_Port, &GPIO_InitStruct);

  /*Configure GPIO pin : OTG_FS_VBUS_Pin */
  GPIO_InitStruct.Pin = OTG_FS_VBUS_Pin;
  GPIO_InitStruct.Mode = GPIO_MODE_INPUT;
  GPIO_InitStruct.Pull = GPIO_NOPULL;
  HAL_GPIO_Init(OTG_FS_VBUS_GPIO_Port, &GPIO_InitStruct);

  /*Configure GPIO pin : Audio_INT_Pin */
  GPIO_InitStruct.Pin = Audio_INT_Pin;
  GPIO_InitStruct.Mode = GPIO_MODE_EVT_RISING;
  GPIO_InitStruct.Pull = GPIO_NOPULL;
  HAL_GPIO_Init(Audio_INT_GPIO_Port, &GPIO_InitStruct);

  /*Configure GPIO pins : OTG_FS_P_Pin OTG_FS_N_Pin OTG_FS_ID_Pin */
  GPIO_InitStruct.Pin = OTG_FS_P_Pin|OTG_FS_N_Pin|OTG_FS_ID_Pin;
  GPIO_InitStruct.Mode = GPIO_MODE_AF_PP;
  GPIO_InitStruct.Pull = GPIO_NOPULL;
  GPIO_InitStruct.Speed = GPIO_SPEED_FREQ_VERY_HIGH;
  GPIO_InitStruct.Alternate = GPIO_AF10_OTG_FS;
  HAL_GPIO_Init(GPIOA, &GPIO_InitStruct);

  /*Configure GPIO pins : SAI2_MCLKA_Pin SAI2_SCKA_Pin SAI2_FSA_Pin SAI2_SDA_Pin */
  GPIO_InitStruct.Pin = SAI2_MCLKA_Pin|SAI2_SCKA_Pin|SAI2_FSA_Pin|SAI2_SDA_Pin;
  GPIO_InitStruct.Mode = GPIO_MODE_AF_PP;
  GPIO_InitStruct.Pull = GPIO_NOPULL;
  GPIO_InitStruct.Speed = GPIO_SPEED_FREQ_LOW;
  GPIO_InitStruct.Alternate = GPIO_AF10_SAI2;
  HAL_GPIO_Init(GPIOI, &GPIO_InitStruct);

  /*Configure GPIO pin : SAI2_SDB_Pin */
  GPIO_InitStruct.Pin = SAI2_SDB_Pin;
  GPIO_InitStruct.Mode = GPIO_MODE_AF_PP;
  GPIO_InitStruct.Pull = GPIO_NOPULL;
  GPIO_InitStruct.Speed = GPIO_SPEED_FREQ_LOW;
  GPIO_InitStruct.Alternate = GPIO_AF10_SAI2;
  HAL_GPIO_Init(SAI2_SDB_GPIO_Port, &GPIO_InitStruct);

  /*Configure GPIO pin : OTG_FS_PowerSwitchOn_Pin */
  GPIO_InitStruct.Pin = OTG_FS_PowerSwitchOn_Pin;
  GPIO_InitStruct.Mode = GPIO_MODE_OUTPUT_PP;
  GPIO_InitStruct.Pull = GPIO_NOPULL;
  GPIO_InitStruct.Speed = GPIO_SPEED_FREQ_LOW;
  HAL_GPIO_Init(OTG_FS_PowerSwitchOn_GPIO_Port, &GPIO_InitStruct);

  /*Configure GPIO pin : DCMI_D5_Pin */
  GPIO_InitStruct.Pin = DCMI_D5_Pin;
  GPIO_InitStruct.Mode = GPIO_MODE_AF_PP;
  GPIO_InitStruct.Pull = GPIO_NOPULL;
  GPIO_InitStruct.Speed = GPIO_SPEED_FREQ_LOW;
  GPIO_InitStruct.Alternate = GPIO_AF13_DCMI;
  HAL_GPIO_Init(DCMI_D5_GPIO_Port, &GPIO_InitStruct);

  /*Configure GPIO pins : ARDUINO_D7_Pin ARDUINO_D8_Pin LCD_DISP_Pin */
  GPIO_InitStruct.Pin = ARDUINO_D7_Pin|ARDUINO_D8_Pin|LCD_DISP_Pin;
  GPIO_InitStruct.Mode = GPIO_MODE_OUTPUT_PP;
  GPIO_InitStruct.Pull = GPIO_NOPULL;
  GPIO_InitStruct.Speed = GPIO_SPEED_FREQ_LOW;
  HAL_GPIO_Init(GPIOI, &GPIO_InitStruct);

  /*Configure GPIO pin : uSD_Detect_Pin */
  GPIO_InitStruct.Pin = uSD_Detect_Pin;
  GPIO_InitStruct.Mode = GPIO_MODE_INPUT;
  GPIO_InitStruct.Pull = GPIO_NOPULL;
  HAL_GPIO_Init(uSD_Detect_GPIO_Port, &GPIO_InitStruct);

  /*Configure GPIO pin : LCD_BL_CTRL_Pin */
  GPIO_InitStruct.Pin = LCD_BL_CTRL_Pin;
  GPIO_InitStruct.Mode = GPIO_MODE_OUTPUT_PP;
  GPIO_InitStruct.Pull = GPIO_NOPULL;
  GPIO_InitStruct.Speed = GPIO_SPEED_FREQ_LOW;
  HAL_GPIO_Init(LCD_BL_CTRL_GPIO_Port, &GPIO_InitStruct);

  /*Configure GPIO pin : DCMI_VSYNC_Pin */
  GPIO_InitStruct.Pin = DCMI_VSYNC_Pin;
  GPIO_InitStruct.Mode = GPIO_MODE_AF_PP;
  GPIO_InitStruct.Pull = GPIO_NOPULL;
  GPIO_InitStruct.Speed = GPIO_SPEED_FREQ_LOW;
  GPIO_InitStruct.Alternate = GPIO_AF13_DCMI;
  HAL_GPIO_Init(DCMI_VSYNC_GPIO_Port, &GPIO_InitStruct);

  /*Configure GPIO pin : OTG_FS_OverCurrent_Pin */
  GPIO_InitStruct.Pin = OTG_FS_OverCurrent_Pin;
  GPIO_InitStruct.Mode = GPIO_MODE_INPUT;
  GPIO_InitStruct.Pull = GPIO_NOPULL;
  HAL_GPIO_Init(OTG_FS_OverCurrent_GPIO_Port, &GPIO_InitStruct);

  /*Configure GPIO pin : SDMMC_D0_Pin */
  GPIO_InitStruct.Pin = SDMMC_D0_Pin;
  GPIO_InitStruct.Mode = GPIO_MODE_AF_PP;
  GPIO_InitStruct.Pull = GPIO_NOPULL;
  GPIO_InitStruct.Speed = GPIO_SPEED_FREQ_VERY_HIGH;
  GPIO_InitStruct.Alternate = GPIO_AF12_SDMMC1;
  HAL_GPIO_Init(SDMMC_D0_GPIO_Port, &GPIO_InitStruct);

  /*Configure GPIO pins : TP3_Pin NC2_Pin */
  GPIO_InitStruct.Pin = TP3_Pin|NC2_Pin;
  GPIO_InitStruct.Mode = GPIO_MODE_INPUT;
  GPIO_InitStruct.Pull = GPIO_NOPULL;
  HAL_GPIO_Init(GPIOH, &GPIO_InitStruct);

  /*Configure GPIO pin : ARDUINO_SCK_D13_Pin */
  GPIO_InitStruct.Pin = ARDUINO_SCK_D13_Pin;
  GPIO_InitStruct.Mode = GPIO_MODE_AF_PP;
  GPIO_InitStruct.Pull = GPIO_NOPULL;
  GPIO_InitStruct.Speed = GPIO_SPEED_FREQ_LOW;
  GPIO_InitStruct.Alternate = GPIO_AF5_SPI2;
  HAL_GPIO_Init(ARDUINO_SCK_D13_GPIO_Port, &GPIO_InitStruct);

  /*Configure GPIO pin : DCMI_PWR_EN_Pin */
  GPIO_InitStruct.Pin = DCMI_PWR_EN_Pin;
  GPIO_InitStruct.Mode = GPIO_MODE_OUTPUT_PP;
  GPIO_InitStruct.Pull = GPIO_NOPULL;
  GPIO_InitStruct.Speed = GPIO_SPEED_FREQ_LOW;
  HAL_GPIO_Init(DCMI_PWR_EN_GPIO_Port, &GPIO_InitStruct);

  /*Configure GPIO pins : DCMI_D4_Pin DCMI_D3_Pin DCMI_D0_Pin DCMI_D2_Pin
                           DCMI_D1_Pin */
  GPIO_InitStruct.Pin = DCMI_D4_Pin|DCMI_D3_Pin|DCMI_D0_Pin|DCMI_D2_Pin
                          |DCMI_D1_Pin;
  GPIO_InitStruct.Mode = GPIO_MODE_AF_PP;
  GPIO_InitStruct.Pull = GPIO_NOPULL;
  GPIO_InitStruct.Speed = GPIO_SPEED_FREQ_LOW;
  GPIO_InitStruct.Alternate = GPIO_AF13_DCMI;
  HAL_GPIO_Init(GPIOH, &GPIO_InitStruct);

  /*Configure GPIO pin : ARDUINO_PWM_CS_D5_Pin */
  GPIO_InitStruct.Pin = ARDUINO_PWM_CS_D5_Pin;
  GPIO_InitStruct.Mode = GPIO_MODE_AF_PP;
  GPIO_InitStruct.Pull = GPIO_NOPULL;
  GPIO_InitStruct.Speed = GPIO_SPEED_FREQ_LOW;
  GPIO_InitStruct.Alternate = GPIO_AF2_TIM5;
  HAL_GPIO_Init(ARDUINO_PWM_CS_D5_GPIO_Port, &GPIO_InitStruct);

  /*Configure GPIO pin : ARDUINO_PWM_D10_Pin */
  GPIO_InitStruct.Pin = ARDUINO_PWM_D10_Pin;
  GPIO_InitStruct.Mode = GPIO_MODE_AF_PP;
  GPIO_InitStruct.Pull = GPIO_NOPULL;
  GPIO_InitStruct.Speed = GPIO_SPEED_FREQ_LOW;
  GPIO_InitStruct.Alternate = GPIO_AF1_TIM1;
  HAL_GPIO_Init(ARDUINO_PWM_D10_GPIO_Port, &GPIO_InitStruct);

  /*Configure GPIO pin : LCD_INT_Pin */
  GPIO_InitStruct.Pin = LCD_INT_Pin;
  GPIO_InitStruct.Mode = GPIO_MODE_IT_RISING;
  GPIO_InitStruct.Pull = GPIO_NOPULL;
  HAL_GPIO_Init(LCD_INT_GPIO_Port, &GPIO_InitStruct);

  /*Configure GPIO pins : ARDUINO_RX_D0_Pin ARDUINO_TX_D1_Pin */
  GPIO_InitStruct.Pin = ARDUINO_RX_D0_Pin|ARDUINO_TX_D1_Pin;
  GPIO_InitStruct.Mode = GPIO_MODE_AF_PP;
  GPIO_InitStruct.Pull = GPIO_NOPULL;
  GPIO_InitStruct.Speed = GPIO_SPEED_FREQ_VERY_HIGH;
  GPIO_InitStruct.Alternate = GPIO_AF8_USART6;
  HAL_GPIO_Init(GPIOC, &GPIO_InitStruct);

  /*Configure GPIO pin : ULPI_NXT_Pin */
  GPIO_InitStruct.Pin = ULPI_NXT_Pin;
  GPIO_InitStruct.Mode = GPIO_MODE_AF_PP;
  GPIO_InitStruct.Pull = GPIO_NOPULL;
  GPIO_InitStruct.Speed = GPIO_SPEED_FREQ_VERY_HIGH;
  GPIO_InitStruct.Alternate = GPIO_AF10_OTG_HS;
  HAL_GPIO_Init(ULPI_NXT_GPIO_Port, &GPIO_InitStruct);

  /*Configure GPIO pins : ARDUINO_D4_Pin ARDUINO_D2_Pin EXT_RST_Pin */
  GPIO_InitStruct.Pin = ARDUINO_D4_Pin|ARDUINO_D2_Pin|EXT_RST_Pin;
  GPIO_InitStruct.Mode = GPIO_MODE_OUTPUT_PP;
  GPIO_InitStruct.Pull = GPIO_NOPULL;
  GPIO_InitStruct.Speed = GPIO_SPEED_FREQ_LOW;
  HAL_GPIO_Init(GPIOG, &GPIO_InitStruct);

  /*Configure GPIO pins : ARDUINO_A4_Pin ARDUINO_A5_Pin ARDUINO_A1_Pin ARDUINO_A2_Pin
                           ARDUINO_A3_Pin */
  GPIO_InitStruct.Pin = ARDUINO_A4_Pin|ARDUINO_A5_Pin|ARDUINO_A1_Pin|ARDUINO_A2_Pin
                          |ARDUINO_A3_Pin;
  GPIO_InitStruct.Mode = GPIO_MODE_ANALOG;
  GPIO_InitStruct.Pull = GPIO_NOPULL;
  HAL_GPIO_Init(GPIOF, &GPIO_InitStruct);

  /*Configure GPIO pins : ULPI_STP_Pin ULPI_DIR_Pin */
  GPIO_InitStruct.Pin = ULPI_STP_Pin|ULPI_DIR_Pin;
  GPIO_InitStruct.Mode = GPIO_MODE_AF_PP;
  GPIO_InitStruct.Pull = GPIO_NOPULL;
  GPIO_InitStruct.Speed = GPIO_SPEED_FREQ_VERY_HIGH;
  GPIO_InitStruct.Alternate = GPIO_AF10_OTG_HS;
  HAL_GPIO_Init(GPIOC, &GPIO_InitStruct);

  /*Configure GPIO pins : RMII_MDC_Pin RMII_RXD0_Pin RMII_RXD1_Pin */
  GPIO_InitStruct.Pin = RMII_MDC_Pin|RMII_RXD0_Pin|RMII_RXD1_Pin;
  GPIO_InitStruct.Mode = GPIO_MODE_AF_PP;
  GPIO_InitStruct.Pull = GPIO_NOPULL;
  GPIO_InitStruct.Speed = GPIO_SPEED_FREQ_VERY_HIGH;
  GPIO_InitStruct.Alternate = GPIO_AF11_ETH;
  HAL_GPIO_Init(GPIOC, &GPIO_InitStruct);

  /*Configure GPIO pin : PB2 */
  GPIO_InitStruct.Pin = GPIO_PIN_2;
  GPIO_InitStruct.Mode = GPIO_MODE_AF_PP;
  GPIO_InitStruct.Pull = GPIO_NOPULL;
  GPIO_InitStruct.Speed = GPIO_SPEED_FREQ_VERY_HIGH;
  GPIO_InitStruct.Alternate = GPIO_AF9_QUADSPI;
  HAL_GPIO_Init(GPIOB, &GPIO_InitStruct);

  /*Configure GPIO pins : QSPI_D1_Pin QSPI_D3_Pin QSPI_D0_Pin */
  GPIO_InitStruct.Pin = QSPI_D1_Pin|QSPI_D3_Pin|QSPI_D0_Pin;
  GPIO_InitStruct.Mode = GPIO_MODE_AF_PP;
  GPIO_InitStruct.Pull = GPIO_NOPULL;
  GPIO_InitStruct.Speed = GPIO_SPEED_FREQ_VERY_HIGH;
  GPIO_InitStruct.Alternate = GPIO_AF9_QUADSPI;
  HAL_GPIO_Init(GPIOD, &GPIO_InitStruct);

  /*Configure GPIO pin : RMII_RXER_Pin */
  GPIO_InitStruct.Pin = RMII_RXER_Pin;
  GPIO_InitStruct.Mode = GPIO_MODE_INPUT;
  GPIO_InitStruct.Pull = GPIO_NOPULL;
  HAL_GPIO_Init(RMII_RXER_GPIO_Port, &GPIO_InitStruct);

  /*Configure GPIO pins : RMII_REF_CLK_Pin RMII_MDIO_Pin RMII_CRS_DV_Pin */
  GPIO_InitStruct.Pin = RMII_REF_CLK_Pin|RMII_MDIO_Pin|RMII_CRS_DV_Pin;
  GPIO_InitStruct.Mode = GPIO_MODE_AF_PP;
  GPIO_InitStruct.Pull = GPIO_NOPULL;
  GPIO_InitStruct.Speed = GPIO_SPEED_FREQ_VERY_HIGH;
  GPIO_InitStruct.Alternate = GPIO_AF11_ETH;
  HAL_GPIO_Init(GPIOA, &GPIO_InitStruct);

  /*Configure GPIO pin : ARDUINO_A0_Pin */
  GPIO_InitStruct.Pin = ARDUINO_A0_Pin;
  GPIO_InitStruct.Mode = GPIO_MODE_ANALOG;
  GPIO_InitStruct.Pull = GPIO_NOPULL;
  HAL_GPIO_Init(ARDUINO_A0_GPIO_Port, &GPIO_InitStruct);

  /*Configure GPIO pins : DCMI_HSYNC_Pin PA6 */
  GPIO_InitStruct.Pin = DCMI_HSYNC_Pin|GPIO_PIN_6;
  GPIO_InitStruct.Mode = GPIO_MODE_AF_PP;
  GPIO_InitStruct.Pull = GPIO_NOPULL;
  GPIO_InitStruct.Speed = GPIO_SPEED_FREQ_LOW;
  GPIO_InitStruct.Alternate = GPIO_AF13_DCMI;
  HAL_GPIO_Init(GPIOA, &GPIO_InitStruct);

  /*Configure GPIO pins : ULPI_CLK_Pin ULPI_D0_Pin */
  GPIO_InitStruct.Pin = ULPI_CLK_Pin|ULPI_D0_Pin;
  GPIO_InitStruct.Mode = GPIO_MODE_AF_PP;
  GPIO_InitStruct.Pull = GPIO_NOPULL;
  GPIO_InitStruct.Speed = GPIO_SPEED_FREQ_VERY_HIGH;
  GPIO_InitStruct.Alternate = GPIO_AF10_OTG_HS;
  HAL_GPIO_Init(GPIOA, &GPIO_InitStruct);

  /*Configure GPIO pin : ARDUINO_PWM_D6_Pin */
  GPIO_InitStruct.Pin = ARDUINO_PWM_D6_Pin;
  GPIO_InitStruct.Mode = GPIO_MODE_AF_PP;
  GPIO_InitStruct.Pull = GPIO_NOPULL;
  GPIO_InitStruct.Speed = GPIO_SPEED_FREQ_LOW;
  GPIO_InitStruct.Alternate = GPIO_AF9_TIM12;
  HAL_GPIO_Init(ARDUINO_PWM_D6_GPIO_Port, &GPIO_InitStruct);

  /*Configure GPIO pins : ARDUINO_MISO_D12_Pin ARDUINO_MOSI_PWM_D11_Pin */
  GPIO_InitStruct.Pin = ARDUINO_MISO_D12_Pin|ARDUINO_MOSI_PWM_D11_Pin;
  GPIO_InitStruct.Mode = GPIO_MODE_AF_PP;
  GPIO_InitStruct.Pull = GPIO_NOPULL;
  GPIO_InitStruct.Speed = GPIO_SPEED_FREQ_LOW;
  GPIO_InitStruct.Alternate = GPIO_AF5_SPI2;
  HAL_GPIO_Init(GPIOB, &GPIO_InitStruct);

  /* EXTI interrupt init*/
  HAL_NVIC_SetPriority(EXTI15_10_IRQn, 5, 0);
  HAL_NVIC_EnableIRQ(EXTI15_10_IRQn);

}

/* USER CODE BEGIN 4 */
void HAL_GPIO_EXTI_Callback(uint16_t GPIO_Pin)
{
	if(GPIO_Pin == LCD_INT_Pin)
	{
		touch_screen_it = 1;
//		BSP_TS_ITClear();
	}
}

void Display_DemoDescription(void)
{
  uint8_t desc[50];

  /* Set LCD Foreground Layer  */
  BSP_LCD_SelectLayer(LTDC_ACTIVE_LAYER);

  BSP_LCD_SetFont(&LCD_DEFAULT_FONT);

  /* Clear the LCD */
  BSP_LCD_SetBackColor(LCD_COLOR_WHITE);
  BSP_LCD_Clear(LCD_COLOR_WHITE);

  /* Set the LCD Text Color */
  BSP_LCD_SetTextColor(LCD_COLOR_DARKBLUE);

  /* Display LCD messages */
  BSP_LCD_DisplayStringAt(0, 10, (uint8_t *)"STM32F746G BSP", CENTER_MODE);
  BSP_LCD_DisplayStringAt(0, 35, (uint8_t *)"Drivers examples", CENTER_MODE);

  /* Draw Bitmap */
  BSP_LCD_DrawBitmap((BSP_LCD_GetXSize() - 80) / 2, 65, (uint8_t *)stlogo);

  BSP_LCD_SetFont(&Font12);
  BSP_LCD_DisplayStringAt(0, BSP_LCD_GetYSize() - 20, (uint8_t *)"Copyright (c) STMicroelectronics 2015", CENTER_MODE);

  BSP_LCD_SetFont(&Font16);
  BSP_LCD_SetTextColor(LCD_COLOR_BLUE);
  BSP_LCD_FillRect(0, BSP_LCD_GetYSize() / 2 + 15, BSP_LCD_GetXSize(), 60);
  BSP_LCD_SetTextColor(LCD_COLOR_WHITE);
  BSP_LCD_SetBackColor(LCD_COLOR_BLUE);
  BSP_LCD_DisplayStringAt(0, BSP_LCD_GetYSize() / 2 + 30, (uint8_t *)"Press User Button to start :", CENTER_MODE);
  sprintf((char *)desc, "%s example", "BSP");
  BSP_LCD_DisplayStringAt(0, BSP_LCD_GetYSize() / 2 + 45, (uint8_t *)desc, CENTER_MODE);
}
/* in draw_utils.c
void Display_Osc(){
	BSP_LCD_Clear(LCD_COLOR_BLACK);
	BSP_LCD_SetBackColor(LCD_COLOR_BLACK);
	BSP_LCD_SetTextColor(LCD_COLOR_YELLOW);
	BSP_LCD_DrawRect(0, 0, 159, 50);
	BSP_LCD_DisplayStringAt(0, LINE(1), (uint8_t *)"Oscilloscope", LEFT_MODE);
	BSP_LCD_DisplayStringAt(0, LINE(1), (uint8_t *)"Sig_gen", CENTER_MODE);
	BSP_LCD_DisplayStringAt(0, LINE(1), (uint8_t *)"Filter", RIGHT_MODE);

	BSP_LCD_DisplayStringAt(0, LINE(16), (uint8_t *)"Full Screen", RIGHT_MODE);
	BSP_LCD_DrawRect(480 - FULL_SCREEN_BUT_X, 272 - FULL_SCREEN_BUT_Y, FULL_SCREEN_BUT_X - 1, FULL_SCREEN_BUT_Y);

	char buffer[50];
	sprintf(buffer, "trigger: %f", osc_trigger);
	BSP_LCD_DisplayStringAt(0, LINE(15), (uint8_t *)buffer, LEFT_MODE);
}

void Display_pure(){
	BSP_LCD_Clear(LCD_COLOR_BLACK);
	BSP_LCD_SetBackColor(LCD_COLOR_BLACK);
	BSP_LCD_SetTextColor(LCD_COLOR_YELLOW);

//	char buffer[50];
//	sprintf(buffer, "Vpp: %f", osc_Vpp);
//	BSP_LCD_DisplayStringAt(0, LINE(16), (uint8_t *)buffer, LEFT_MODE);
//	sprintf(buffer, "f: %f", osc_freq);
//	BSP_LCD_DisplayStringAt(0, LINE(15), (uint8_t *)buffer, LEFT_MODE);
//	sprintf(buffer, "T: %f", osc_T);
//	BSP_LCD_DisplayStringAt(0, LINE(15), (uint8_t *)buffer, RIGHT_MODE);
//	sprintf(buffer, "V: %f", osc_V);
//	BSP_LCD_DisplayStringAt(0, LINE(16), (uint8_t *)buffer, RIGHT_MODE);
//
//	BSP_LCD_DisplayStringAt(0, LINE(1), (uint8_t *)"OSC", LEFT_MODE);
//	BSP_LCD_DisplayStringAt(0, LINE(1), (uint8_t *)"FIL", RIGHT_MODE);
}

void Display_Sig_gen(){
	BSP_LCD_Clear(LCD_COLOR_BLACK);
	BSP_LCD_SetBackColor(LCD_COLOR_BLACK);
	BSP_LCD_SetTextColor(LCD_COLOR_YELLOW);
	BSP_LCD_DisplayStringAt(0, LINE(1), (uint8_t *)"Oscilloscope", LEFT_MODE);
	BSP_LCD_DrawRect(160, 0, 159, 50);
	BSP_LCD_DisplayStringAt(0, LINE(1), (uint8_t *)"Sig_gen", CENTER_MODE);
	BSP_LCD_DisplayStringAt(0, LINE(1), (uint8_t *)"Filter", RIGHT_MODE);

	BSP_LCD_DisplayStringAt(0, LINE(5), (uint8_t *)"Select your waveform: ", LEFT_MODE);
	BSP_LCD_DisplayStringAt(0, LINE(8), (uint8_t *)"SINE", LEFT_MODE);
	BSP_LCD_DisplayStringAt(160, LINE(8), (uint8_t *)"SQUARE", LEFT_MODE);
	BSP_LCD_DisplayStringAt(320, LINE(8), (uint8_t *)"TRIANGLE", LEFT_MODE);
	BSP_LCD_DrawRect(160*current_waveform, 100, WAVEFORM_SELECT_BOX_X - 1, WAVEFORM_SELECT_BOX_Y);

	char buffer[50];
	sprintf(buffer, "Vpp: %f", waveform_mag);
	BSP_LCD_DisplayStringAt(0, LINE(10), (uint8_t *)buffer, LEFT_MODE);
	sprintf(buffer, "Freq: %f", waveform_freq);
	BSP_LCD_DisplayStringAt(0, LINE(12), (uint8_t *)buffer, LEFT_MODE);
	sprintf(buffer, "Duty ratio (for square): %f", waveform_duty);
	BSP_LCD_DisplayStringAt(0, LINE(14), (uint8_t *)buffer, LEFT_MODE);
}

void Display_Filter(){
	BSP_LCD_Clear(LCD_COLOR_BLACK);
	BSP_LCD_SetBackColor(LCD_COLOR_BLACK);
	BSP_LCD_SetTextColor(LCD_COLOR_YELLOW);
	BSP_LCD_DisplayStringAt(0, LINE(1), (uint8_t *)"Oscilloscope", LEFT_MODE);
	BSP_LCD_DisplayStringAt(0, LINE(1), (uint8_t *)"Sig_gen", CENTER_MODE);
	BSP_LCD_DisplayStringAt(0, LINE(1), (uint8_t *)"Filter", RIGHT_MODE);
	BSP_LCD_DrawRect(320, 0, 159, 50);

	BSP_LCD_DisplayStringAt(0, LINE(13), (uint8_t *)"Select your filter: ", LEFT_MODE);
	BSP_LCD_DisplayStringAt(96, LINE(14), (uint8_t *)"LPF", LEFT_MODE);
	BSP_LCD_DisplayStringAt(192, LINE(14), (uint8_t *)"HPF", LEFT_MODE);
	BSP_LCD_DisplayStringAt(288, LINE(14), (uint8_t *)"BPF", LEFT_MODE);
	BSP_LCD_DisplayStringAt(384, LINE(14), (uint8_t *)"BSF", LEFT_MODE);
	BSP_LCD_DrawRect(FILTER_SELECT_BOX_X * (1 + current_filter), 222, FILTER_SELECT_BOX_X, FILTER_SELECT_BOX_Y);

	BSP_LCD_DisplayStringAt(0, LINE(7), (uint8_t *)"GO!", CENTER_MODE);

	char buffer[50];
	sprintf(buffer, "fc1 (not used in LPF, HPF): %f", fir_fc1);
	BSP_LCD_DisplayStringAt(50, LINE(15), (uint8_t *)buffer, LEFT_MODE);
	sprintf(buffer, "fc2 (fc for LPF, HPF): %f", fir_fc2);
	BSP_LCD_DisplayStringAt(50, LINE(16), (uint8_t *)buffer, LEFT_MODE);
}

void Select_Waveform(uint16_t waveform){
	for(int i = 0; i < 3; ++i){
		BSP_LCD_SetTextColor(LCD_COLOR_BLACK);
		BSP_LCD_DrawRect(WAVEFORM_SELECT_BOX_X*i, 100, WAVEFORM_SELECT_BOX_X - 1, WAVEFORM_SELECT_BOX_Y);
	}
	BSP_LCD_SetTextColor(LCD_COLOR_YELLOW);
	switch(waveform){
	case 0:
		BSP_LCD_DrawRect(0, 100, WAVEFORM_SELECT_BOX_X - 1, WAVEFORM_SELECT_BOX_Y);
		current_waveform = SIN;
		break;
	case 1:
		BSP_LCD_DrawRect(160, 100, WAVEFORM_SELECT_BOX_X - 1, WAVEFORM_SELECT_BOX_Y);
		current_waveform = SQR;
		break;
	case 2:
		BSP_LCD_DrawRect(320, 100, WAVEFORM_SELECT_BOX_X - 1, WAVEFORM_SELECT_BOX_Y);
		current_waveform = TRI;
		break;
	}
}

void Select_Filter(uint16_t selected_fir){
	for(int i = 0; i < 4; ++i){
		BSP_LCD_SetTextColor(LCD_COLOR_BLACK);
		BSP_LCD_DrawRect(FILTER_SELECT_BOX_X*(i+1), 222, FILTER_SELECT_BOX_X, FILTER_SELECT_BOX_Y);
	}
	BSP_LCD_SetTextColor(LCD_COLOR_YELLOW);
	switch(selected_fir){
	case 0:
		BSP_LCD_DrawRect(FILTER_SELECT_BOX_X, 222, FILTER_SELECT_BOX_X, FILTER_SELECT_BOX_Y);
		current_filter = FIR_LOW;
		break;
	case 1:
		BSP_LCD_DrawRect(FILTER_SELECT_BOX_X * 2, 222, FILTER_SELECT_BOX_X, FILTER_SELECT_BOX_Y);
		current_filter = FIR_HIGH;
		break;
	case 2:
		BSP_LCD_DrawRect(FILTER_SELECT_BOX_X * 3, 222, FILTER_SELECT_BOX_X, FILTER_SELECT_BOX_Y);
		current_filter = FIR_BANDPASS;
		break;
	case 3:
		BSP_LCD_DrawRect(FILTER_SELECT_BOX_X * 4, 222, FILTER_SELECT_BOX_X, FILTER_SELECT_BOX_Y);
		current_filter = FIR_BANDSTOP;
		break;
	}
}

void touch_screen_response(){
	BSP_TS_ITClear();
	BSP_TS_GetState(&touch_screen_state);
	BSP_TS_Get_GestureId(&touch_screen_state);
	if(touch_screen_state.gestureId != 0)
		gesture = touch_screen_state.gestureId;
	touch_screen_it = 0;
	if(touch_screen_state.touchX[0] > 320) anomaly_flag = 1;
	if(current_mode == PUR){
		if(touch_screen_state.touchY[0] < 50){
			if(touch_screen_state.touchX[0] < 40){
				current_mode = OSC;
				Display_Osc();
				apply_filter = 0;
			}else if(touch_screen_state.touchX[0] > 440){
				current_mode = FIL;
				Display_Filter();
				apply_filter = 1;
			}
		}
		return;
	}
	if(touch_screen_state.touchX[0] < 320 && touch_screen_state.touchX[0] > 160 && touch_screen_state.touchY[0] < 50){
		Display_Sig_gen();
		current_mode = SIG;
	}
	if(touch_screen_state.touchX[0] < 160 && touch_screen_state.touchY[0] < 50){
		current_mode = OSC;
		Display_Osc();
		apply_filter = 0;
	}
	if(touch_screen_state.touchX[0] > 320 && touch_screen_state.touchY[0] < 50){
		Display_Filter();
		current_mode = FIL;
		apply_filter = 1;
	}
	switch(current_mode){
	case OSC:
		if(touch_screen_state.touchY[0] > SCREEN_Y - FULL_SCREEN_BUT_Y && touch_screen_state.touchX[0] > SCREEN_X - FULL_SCREEN_BUT_X){
			current_mode = PUR;
			Display_pure();
		}
		return;
	case SIG:
		if(touch_screen_state.touchY[0] > 100 && touch_screen_state.touchY[0] < 200){
			for(uint16_t j = 0; j < 3; j++){
				if((touch_screen_state.touchX[0] > (WAVEFORM_SELECT_BOX_X*j)) && (touch_screen_state.touchX[0] < WAVEFORM_SELECT_BOX_X * (1 + j))){
					Select_Waveform(j);
					break;
				}
			}
		}
		return;
	case FIL:
		if(touch_screen_state.touchY[0] > 222){
			for(uint16_t j = 0; j < 4; ++j){
				if((touch_screen_state.touchX[0] > FILTER_SELECT_BOX_X * (j + 1)) && (touch_screen_state.touchX[0] < FILTER_SELECT_BOX_X * (j + 2))){
					Select_Filter(j);
					break;
				}
			}
		}else if(touch_screen_state.touchY[0] > 50){
			current_mode = PUR;
			Display_pure();
		}
		return;
	default:
		return;
	}
}

void float_to_string(float val, char *str, int decimal_places) {
    if (val < 0) {
        *str++ = '-';
        val = -val;
    }

    int int_part = (int)val;
    int frac_part = (int)((val - int_part) * pow(10, decimal_places));

    // Convert integer part
    itoa(int_part, str, 10);
    while (*str) str++;  // Move pointer to end

    *str++ = '.';

    // Convert fractional part with leading zero if needed
    if (decimal_places == 2 && frac_part < 10)
        *str++ = '0';

    itoa(frac_part, str, 10);
}

void buffer_maker(float val, const char *prefix, char *out_buffer) {
    char numbuff[20];
    float_to_string(val, numbuff, 2);

    strcpy(out_buffer, prefix);      // Copy prefix like "Vpp: "
    strcat(out_buffer, numbuff);     // Append converted float
}

void draw_waveform(){
	BSP_LCD_DisplayStringAt(0, LINE(1), (uint8_t *)"OSC", LEFT_MODE);
	BSP_LCD_DisplayStringAt(0, LINE(1), (uint8_t *)"FIL", RIGHT_MODE);

	char buffer[50];
	buffer_maker(osc_Vpp, "Vpp: ", buffer);
	BSP_LCD_DisplayStringAt(0, LINE(16), (uint8_t *)buffer, LEFT_MODE);
	buffer_maker(osc_freq, "f: ", buffer);
	BSP_LCD_DisplayStringAt(0, LINE(15), (uint8_t *)buffer, LEFT_MODE);
	buffer_maker(osc_T, "T: ", buffer);
	BSP_LCD_DisplayStringAt(0, LINE(15), (uint8_t *)buffer, RIGHT_MODE);
	buffer_maker(osc_V, "V: ", buffer);
	BSP_LCD_DisplayStringAt(0, LINE(16), (uint8_t *)buffer, RIGHT_MODE);

	for(int j = 0; j < 400; ++j){
		uint16_t db_index = (trigger_index - 199 + 400 + j) % 400;
		float point_y = 255 - databuffer[db_index];
		point_y = (point_y/255.0) * 215;
		drawbuffer[j] = (uint8_t) point_y;
		BSP_LCD_SetTextColor(LCD_COLOR_BLACK);
		BSP_LCD_DrawRect(j + 40, prevdrawbuffer[j], 1, 1);
		BSP_LCD_SetTextColor(LCD_COLOR_YELLOW);
		BSP_LCD_DrawRect(j + 40, drawbuffer[j], 1, 1);
		prevdrawbuffer[j] = drawbuffer[j];
		databuffer[db_index] = (databuffer[db_index] + 5) % 255;
	}
}
*/

/* USER CODE END 4 */

void StartDefaultTask(void *argument)
{
  for(;;)
  {
    osDelay(1);
  }
}

void StartTSResponse(void *argument)
{
  /* USER CODE BEGIN StartTSResponse */
  /* Infinite loop */
  for(;;)
  {
	if(touch_screen_it) touch_screen_response();
//	BSP_TS_ITClear();
//    osDelay(1);
	HAL_Delay(1);
  }
  /* USER CODE END StartTSResponse */
}

void StartOscDrawing(void *argument)
{
  /* USER CODE BEGIN StartOscDrawing */
  /* Infinite loop */
  for(;;)
  {
	if(current_mode == PUR){
		HAL_Delay(1);
		draw_waveform();

//		BSP_LCD_DisplayStringAt(0, LINE(1), (uint8_t *)"OSC", LEFT_MODE);
//		BSP_LCD_DisplayStringAt(0, LINE(1), (uint8_t *)"FIL", RIGHT_MODE);
//
//		char buffer[50];
//		buffer_maker(osc_Vpp, "Vpp: ", buffer);
//		BSP_LCD_DisplayStringAt(0, LINE(16), (uint8_t *)buffer, LEFT_MODE);
//		buffer_maker(osc_freq, "f: ", buffer);
//		BSP_LCD_DisplayStringAt(0, LINE(15), (uint8_t *)buffer, LEFT_MODE);
//		buffer_maker(osc_T, "T: ", buffer);
//		BSP_LCD_DisplayStringAt(0, LINE(15), (uint8_t *)buffer, RIGHT_MODE);
//		buffer_maker(osc_V, "V: ", buffer);
//		BSP_LCD_DisplayStringAt(0, LINE(16), (uint8_t *)buffer, RIGHT_MODE);
//
//		for(int j = 0; j < 400; ++j){
//			uint16_t db_index = (trigger_index - 199 + 400 + j) % 400;
//			float point_y = 255 - databuffer[db_index];
//			point_y = (point_y/255.0) * 215;
//			drawbuffer[j] = (uint8_t) point_y;
//			BSP_LCD_SetTextColor(LCD_COLOR_BLACK);
//			BSP_LCD_DrawRect(j + 40, prevdrawbuffer[j], 1, 1);
//			BSP_LCD_SetTextColor(LCD_COLOR_YELLOW);
//			BSP_LCD_DrawRect(j + 40, drawbuffer[j], 1, 1);
//			prevdrawbuffer[j] = drawbuffer[j];
//			databuffer[db_index] = (databuffer[db_index] + 5) % 255;
//		}
	}
	HAL_Delay(1);
//    osDelay(1);
  }
  /* USER CODE END StartOscDrawing */
}

void Error_Handler(void)
{
  __disable_irq();
  while (1)
  {
  }
}
